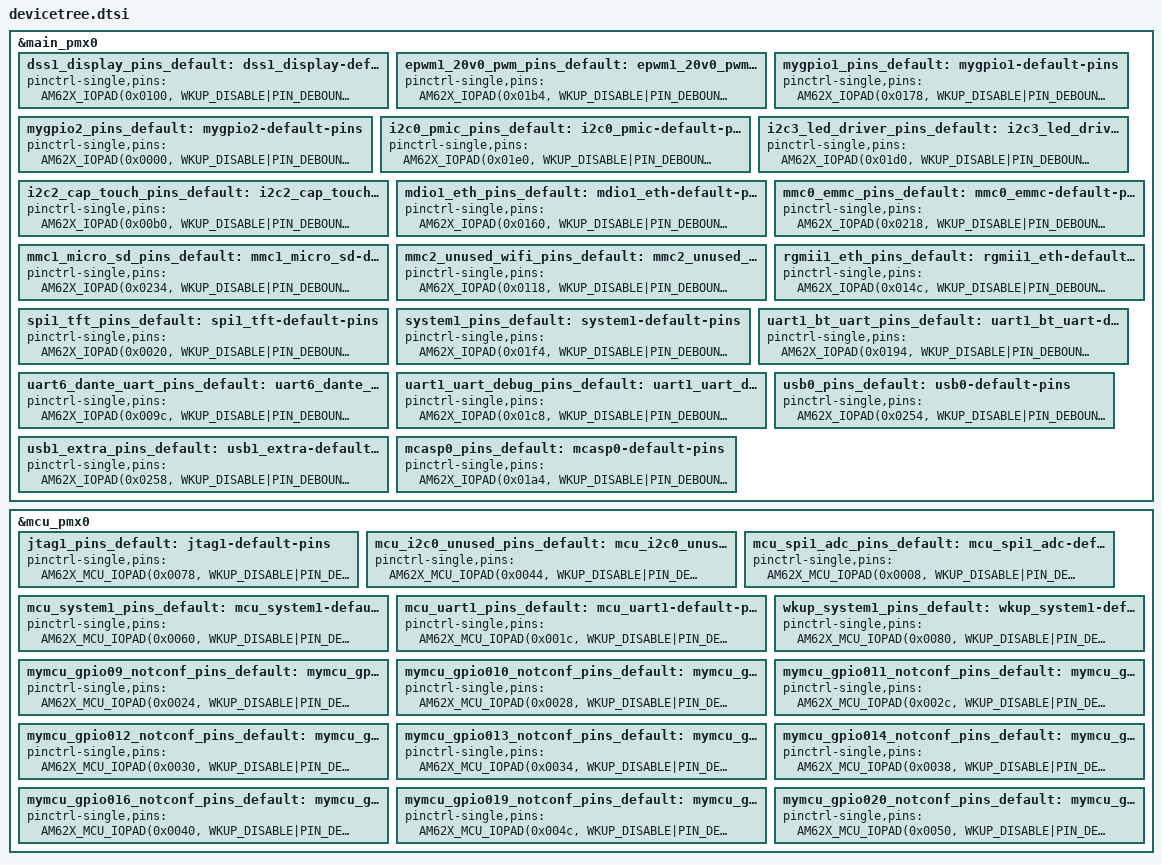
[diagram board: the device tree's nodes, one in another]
/* This file was auto-generated by TI PinMux on 7/21/2026 at 1:33:13 PM. */
/* This file should only be used as a reference. Some pins/peripherals, */
/* depending on your use case, may need additional configuration. */

/* Some or all of the pins from the following groups are not used by the device tree
	ddrss1_ddr_memory
	mcu_osc1
	usb0
	usb1_extra
	wkup_lfosc1
*/

&main_pmx0 {
	dss1_display_pins_default: dss1_display-default-pins {
		pinctrl-single,pins = <
			AM62X_IOPAD(0x0100, WKUP_DISABLE|PIN_DEBOUNCE_DISABLE|PIN_DS_FORCE_DISABLE|PIN_OUTPUT|PIN_DRIVE_STRENGTH_NOMINAL|PIN_DS_ISO_OVERRIDE_DISABLE|PIN_DS_ISO_BYPASS_DISABLE|ACTIVE_STATE_VAL|PIN_DS_INPUT|PIN_SCMITT_TRIGGER_ENABLE, 0) /* (AC25) VOUT0_VSYNC */
			AM62X_IOPAD(0x00f8, WKUP_DISABLE|PIN_DEBOUNCE_DISABLE|PIN_DS_FORCE_DISABLE|PIN_OUTPUT|PIN_DRIVE_STRENGTH_NOMINAL|PIN_DS_ISO_OVERRIDE_DISABLE|PIN_DS_ISO_BYPASS_DISABLE|ACTIVE_STATE_VAL|PIN_DS_INPUT|PIN_SCMITT_TRIGGER_ENABLE, 0) /* (AB24) VOUT0_HSYNC */
			AM62X_IOPAD(0x0104, WKUP_DISABLE|PIN_DEBOUNCE_DISABLE|PIN_DS_FORCE_DISABLE|PIN_OUTPUT|PIN_DRIVE_STRENGTH_NOMINAL|PIN_DS_ISO_OVERRIDE_DISABLE|PIN_DS_ISO_BYPASS_DISABLE|ACTIVE_STATE_VAL|PIN_DS_INPUT|PIN_SCMITT_TRIGGER_ENABLE, 0) /* (AC24) VOUT0_PCLK */
			AM62X_IOPAD(0x00fc, WKUP_DISABLE|PIN_DEBOUNCE_DISABLE|PIN_DS_FORCE_DISABLE|PIN_OUTPUT|PIN_DRIVE_STRENGTH_NOMINAL|PIN_DS_ISO_OVERRIDE_DISABLE|PIN_DS_ISO_BYPASS_DISABLE|ACTIVE_STATE_VAL|PIN_DS_INPUT|PIN_SCMITT_TRIGGER_ENABLE, 0) /* (Y20) VOUT0_DE */
			AM62X_IOPAD(0x00b8, WKUP_DISABLE|PIN_DEBOUNCE_DISABLE|PIN_DS_FORCE_DISABLE|PIN_OUTPUT|PIN_DRIVE_STRENGTH_NOMINAL|PIN_DS_ISO_OVERRIDE_DISABLE|PIN_DS_ISO_BYPASS_DISABLE|ACTIVE_STATE_VAL|PIN_DS_INPUT|PIN_SCMITT_TRIGGER_ENABLE, 0) /* (U22) VOUT0_DATA0 */
			AM62X_IOPAD(0x00bc, WKUP_DISABLE|PIN_DEBOUNCE_DISABLE|PIN_DS_FORCE_DISABLE|PIN_OUTPUT|PIN_DRIVE_STRENGTH_NOMINAL|PIN_DS_ISO_OVERRIDE_DISABLE|PIN_DS_ISO_BYPASS_DISABLE|ACTIVE_STATE_VAL|PIN_DS_INPUT|PIN_SCMITT_TRIGGER_ENABLE, 0) /* (V24) VOUT0_DATA1 */
			AM62X_IOPAD(0x00c0, WKUP_DISABLE|PIN_DEBOUNCE_DISABLE|PIN_DS_FORCE_DISABLE|PIN_OUTPUT|PIN_DRIVE_STRENGTH_NOMINAL|PIN_DS_ISO_OVERRIDE_DISABLE|PIN_DS_ISO_BYPASS_DISABLE|ACTIVE_STATE_VAL|PIN_DS_INPUT|PIN_SCMITT_TRIGGER_ENABLE, 0) /* (W25) VOUT0_DATA2 */
			AM62X_IOPAD(0x00c4, WKUP_DISABLE|PIN_DEBOUNCE_DISABLE|PIN_DS_FORCE_DISABLE|PIN_OUTPUT|PIN_DRIVE_STRENGTH_NOMINAL|PIN_DS_ISO_OVERRIDE_DISABLE|PIN_DS_ISO_BYPASS_DISABLE|ACTIVE_STATE_VAL|PIN_DS_INPUT|PIN_SCMITT_TRIGGER_ENABLE, 0) /* (W24) VOUT0_DATA3 */
			AM62X_IOPAD(0x00c8, WKUP_DISABLE|PIN_DEBOUNCE_DISABLE|PIN_DS_FORCE_DISABLE|PIN_OUTPUT|PIN_DRIVE_STRENGTH_NOMINAL|PIN_DS_ISO_OVERRIDE_DISABLE|PIN_DS_ISO_BYPASS_DISABLE|ACTIVE_STATE_VAL|PIN_DS_INPUT|PIN_SCMITT_TRIGGER_ENABLE, 0) /* (Y25) VOUT0_DATA4 */
			AM62X_IOPAD(0x00cc, WKUP_DISABLE|PIN_DEBOUNCE_DISABLE|PIN_DS_FORCE_DISABLE|PIN_OUTPUT|PIN_DRIVE_STRENGTH_NOMINAL|PIN_DS_ISO_OVERRIDE_DISABLE|PIN_DS_ISO_BYPASS_DISABLE|ACTIVE_STATE_VAL|PIN_DS_INPUT|PIN_SCMITT_TRIGGER_ENABLE, 0) /* (Y24) VOUT0_DATA5 */
			AM62X_IOPAD(0x00d0, WKUP_DISABLE|PIN_DEBOUNCE_DISABLE|PIN_DS_FORCE_DISABLE|PIN_OUTPUT|PIN_DRIVE_STRENGTH_NOMINAL|PIN_DS_ISO_OVERRIDE_DISABLE|PIN_DS_ISO_BYPASS_DISABLE|ACTIVE_STATE_VAL|PIN_DS_INPUT|PIN_SCMITT_TRIGGER_ENABLE, 0) /* (Y23) VOUT0_DATA6 */
			AM62X_IOPAD(0x00d4, WKUP_DISABLE|PIN_DEBOUNCE_DISABLE|PIN_DS_FORCE_DISABLE|PIN_OUTPUT|PIN_DRIVE_STRENGTH_NOMINAL|PIN_DS_ISO_OVERRIDE_DISABLE|PIN_DS_ISO_BYPASS_DISABLE|ACTIVE_STATE_VAL|PIN_DS_INPUT|PIN_SCMITT_TRIGGER_ENABLE, 0) /* (AA25) VOUT0_DATA7 */
			AM62X_IOPAD(0x00d8, WKUP_DISABLE|PIN_DEBOUNCE_DISABLE|PIN_DS_FORCE_DISABLE|PIN_OUTPUT|PIN_DRIVE_STRENGTH_NOMINAL|PIN_DS_ISO_OVERRIDE_DISABLE|PIN_DS_ISO_BYPASS_DISABLE|ACTIVE_STATE_VAL|PIN_DS_INPUT|PIN_SCMITT_TRIGGER_ENABLE, 0) /* (V21) VOUT0_DATA8 */
			AM62X_IOPAD(0x00dc, WKUP_DISABLE|PIN_DEBOUNCE_DISABLE|PIN_DS_FORCE_DISABLE|PIN_OUTPUT|PIN_DRIVE_STRENGTH_NOMINAL|PIN_DS_ISO_OVERRIDE_DISABLE|PIN_DS_ISO_BYPASS_DISABLE|ACTIVE_STATE_VAL|PIN_DS_INPUT|PIN_SCMITT_TRIGGER_ENABLE, 0) /* (W21) VOUT0_DATA9 */
			AM62X_IOPAD(0x00e0, WKUP_DISABLE|PIN_DEBOUNCE_DISABLE|PIN_DS_FORCE_DISABLE|PIN_OUTPUT|PIN_DRIVE_STRENGTH_NOMINAL|PIN_DS_ISO_OVERRIDE_DISABLE|PIN_DS_ISO_BYPASS_DISABLE|ACTIVE_STATE_VAL|PIN_DS_INPUT|PIN_SCMITT_TRIGGER_ENABLE, 0) /* (V20) VOUT0_DATA10 */
			AM62X_IOPAD(0x00e4, WKUP_DISABLE|PIN_DEBOUNCE_DISABLE|PIN_DS_FORCE_DISABLE|PIN_OUTPUT|PIN_DRIVE_STRENGTH_NOMINAL|PIN_DS_ISO_OVERRIDE_DISABLE|PIN_DS_ISO_BYPASS_DISABLE|ACTIVE_STATE_VAL|PIN_DS_INPUT|PIN_SCMITT_TRIGGER_ENABLE, 0) /* (AA23) VOUT0_DATA11 */
			AM62X_IOPAD(0x00e8, WKUP_DISABLE|PIN_DEBOUNCE_DISABLE|PIN_DS_FORCE_DISABLE|PIN_OUTPUT|PIN_DRIVE_STRENGTH_NOMINAL|PIN_DS_ISO_OVERRIDE_DISABLE|PIN_DS_ISO_BYPASS_DISABLE|ACTIVE_STATE_VAL|PIN_DS_INPUT|PIN_SCMITT_TRIGGER_ENABLE, 0) /* (AB25) VOUT0_DATA12 */
			AM62X_IOPAD(0x00ec, WKUP_DISABLE|PIN_DEBOUNCE_DISABLE|PIN_DS_FORCE_DISABLE|PIN_OUTPUT|PIN_DRIVE_STRENGTH_NOMINAL|PIN_DS_ISO_OVERRIDE_DISABLE|PIN_DS_ISO_BYPASS_DISABLE|ACTIVE_STATE_VAL|PIN_DS_INPUT|PIN_SCMITT_TRIGGER_ENABLE, 0) /* (AA24) VOUT0_DATA13 */
			AM62X_IOPAD(0x00f0, WKUP_DISABLE|PIN_DEBOUNCE_DISABLE|PIN_DS_FORCE_DISABLE|PIN_OUTPUT|PIN_DRIVE_STRENGTH_NOMINAL|PIN_DS_ISO_OVERRIDE_DISABLE|PIN_DS_ISO_BYPASS_DISABLE|ACTIVE_STATE_VAL|PIN_DS_INPUT|PIN_SCMITT_TRIGGER_ENABLE, 0) /* (Y22) VOUT0_DATA14 */
			AM62X_IOPAD(0x00f4, WKUP_DISABLE|PIN_DEBOUNCE_DISABLE|PIN_DS_FORCE_DISABLE|PIN_OUTPUT|PIN_DRIVE_STRENGTH_NOMINAL|PIN_DS_ISO_OVERRIDE_DISABLE|PIN_DS_ISO_BYPASS_DISABLE|ACTIVE_STATE_VAL|PIN_DS_INPUT|PIN_SCMITT_TRIGGER_ENABLE, 0) /* (AA21) VOUT0_DATA15 */
			AM62X_IOPAD(0x005c, WKUP_DISABLE|PIN_DEBOUNCE_DISABLE|PIN_DS_FORCE_DISABLE|PIN_OUTPUT|PIN_DRIVE_STRENGTH_NOMINAL|PIN_DS_ISO_OVERRIDE_DISABLE|PIN_DS_ISO_BYPASS_DISABLE|ACTIVE_STATE_VAL|PIN_DS_INPUT|PIN_SCMITT_TRIGGER_ENABLE, 1) /* (R24) GPMC0_AD8.VOUT0_DATA16 */
			AM62X_IOPAD(0x0060, WKUP_DISABLE|PIN_DEBOUNCE_DISABLE|PIN_DS_FORCE_DISABLE|PIN_OUTPUT|PIN_DRIVE_STRENGTH_NOMINAL|PIN_DS_ISO_OVERRIDE_DISABLE|PIN_DS_ISO_BYPASS_DISABLE|ACTIVE_STATE_VAL|PIN_DS_INPUT|PIN_SCMITT_TRIGGER_ENABLE, 1) /* (R25) GPMC0_AD9.VOUT0_DATA17 */
			AM62X_IOPAD(0x0064, WKUP_DISABLE|PIN_DEBOUNCE_DISABLE|PIN_DS_FORCE_DISABLE|PIN_OUTPUT|PIN_DRIVE_STRENGTH_NOMINAL|PIN_DS_ISO_OVERRIDE_DISABLE|PIN_DS_ISO_BYPASS_DISABLE|ACTIVE_STATE_VAL|PIN_DS_INPUT|PIN_SCMITT_TRIGGER_ENABLE, 1) /* (T25) GPMC0_AD10.VOUT0_DATA18 */
			AM62X_IOPAD(0x0068, WKUP_DISABLE|PIN_DEBOUNCE_DISABLE|PIN_DS_FORCE_DISABLE|PIN_OUTPUT|PIN_DRIVE_STRENGTH_NOMINAL|PIN_DS_ISO_OVERRIDE_DISABLE|PIN_DS_ISO_BYPASS_DISABLE|ACTIVE_STATE_VAL|PIN_DS_INPUT|PIN_SCMITT_TRIGGER_ENABLE, 1) /* (R21) GPMC0_AD11.VOUT0_DATA19 */
			AM62X_IOPAD(0x006c, WKUP_DISABLE|PIN_DEBOUNCE_DISABLE|PIN_DS_FORCE_DISABLE|PIN_OUTPUT|PIN_DRIVE_STRENGTH_NOMINAL|PIN_DS_ISO_OVERRIDE_DISABLE|PIN_DS_ISO_BYPASS_DISABLE|ACTIVE_STATE_VAL|PIN_DS_INPUT|PIN_SCMITT_TRIGGER_ENABLE, 1) /* (T22) GPMC0_AD12.VOUT0_DATA20 */
			AM62X_IOPAD(0x0070, WKUP_DISABLE|PIN_DEBOUNCE_DISABLE|PIN_DS_FORCE_DISABLE|PIN_OUTPUT|PIN_DRIVE_STRENGTH_NOMINAL|PIN_DS_ISO_OVERRIDE_DISABLE|PIN_DS_ISO_BYPASS_DISABLE|ACTIVE_STATE_VAL|PIN_DS_INPUT|PIN_SCMITT_TRIGGER_ENABLE, 1) /* (T24) GPMC0_AD13.VOUT0_DATA21 */
			AM62X_IOPAD(0x0074, WKUP_DISABLE|PIN_DEBOUNCE_DISABLE|PIN_DS_FORCE_DISABLE|PIN_OUTPUT|PIN_DRIVE_STRENGTH_NOMINAL|PIN_DS_ISO_OVERRIDE_DISABLE|PIN_DS_ISO_BYPASS_DISABLE|ACTIVE_STATE_VAL|PIN_DS_INPUT|PIN_SCMITT_TRIGGER_ENABLE, 1) /* (U25) GPMC0_AD14.VOUT0_DATA22 */
			AM62X_IOPAD(0x0078, WKUP_DISABLE|PIN_DEBOUNCE_DISABLE|PIN_DS_FORCE_DISABLE|PIN_OUTPUT|PIN_DRIVE_STRENGTH_NOMINAL|PIN_DS_ISO_OVERRIDE_DISABLE|PIN_DS_ISO_BYPASS_DISABLE|ACTIVE_STATE_VAL|PIN_DS_INPUT|PIN_SCMITT_TRIGGER_ENABLE, 1) /* (U24) GPMC0_AD15.VOUT0_DATA23 */
		>;
	};
	epwm1_20v0_pwm_pins_default: epwm1_20v0_pwm-default-pins {
		pinctrl-single,pins = <
			AM62X_IOPAD(0x01b4, WKUP_DISABLE|PIN_DEBOUNCE_DISABLE|PIN_DS_FORCE_DISABLE|PIN_OUTPUT|PIN_DRIVE_STRENGTH_NOMINAL|PIN_DS_ISO_OVERRIDE_DISABLE|PIN_DS_ISO_BYPASS_DISABLE|ACTIVE_STATE_VAL|PIN_DS_INPUT|PIN_SCMITT_TRIGGER_ENABLE, 2) /* (A13) SPI0_CS0.EHRPWM0_A */
		>;
	};
	mygpio1_pins_default: mygpio1-default-pins {
		pinctrl-single,pins = <
			AM62X_IOPAD(0x0178, WKUP_DISABLE|PIN_DEBOUNCE_DISABLE|PIN_DS_FORCE_DISABLE|PIN_INPUT|PIN_DRIVE_STRENGTH_NOMINAL|PIN_DS_ISO_OVERRIDE_DISABLE|PIN_DS_ISO_BYPASS_DISABLE|ACTIVE_STATE_VAL|PIN_DS_INPUT|PIN_SCMITT_TRIGGER_ENABLE, 7) /* (AC20) RGMII2_TD3.GPIO1_0 GPIO1_0_USB0_Ocn */
			AM62X_IOPAD(0x0028, WKUP_DISABLE|PIN_DEBOUNCE_DISABLE|PIN_DS_FORCE_DISABLE|PIN_INPUT|PIN_DRIVE_STRENGTH_NOMINAL|PIN_DS_ISO_OVERRIDE_DISABLE|PIN_DS_ISO_BYPASS_DISABLE|ACTIVE_STATE_VAL|PIN_DS_INPUT|PIN_SCMITT_TRIGGER_ENABLE, 7) /* (J22) OSPI0_D7.GPIO0_10 GPIO0_10_LED1 */
			AM62X_IOPAD(0x003c, WKUP_DISABLE|PIN_DEBOUNCE_DISABLE|PIN_DS_FORCE_DISABLE|PIN_INPUT|PIN_DRIVE_STRENGTH_NOMINAL|PIN_DS_ISO_OVERRIDE_DISABLE|PIN_DS_ISO_BYPASS_DISABLE|ACTIVE_STATE_VAL|PIN_DS_INPUT|PIN_SCMITT_TRIGGER_ENABLE, 7) /* (M25) GPMC0_AD0.GPIO0_15 BOOTMODE00 */
			AM62X_IOPAD(0x0040, WKUP_DISABLE|PIN_DEBOUNCE_DISABLE|PIN_DS_FORCE_DISABLE|PIN_INPUT|PIN_DRIVE_STRENGTH_NOMINAL|PIN_DS_ISO_OVERRIDE_DISABLE|PIN_DS_ISO_BYPASS_DISABLE|ACTIVE_STATE_VAL|PIN_DS_INPUT|PIN_SCMITT_TRIGGER_ENABLE, 7) /* (N23) GPMC0_AD1.GPIO0_16 BOOTMODE01_eMMC_nRST */
			AM62X_IOPAD(0x0044, WKUP_DISABLE|PIN_DEBOUNCE_DISABLE|PIN_DS_FORCE_DISABLE|PIN_INPUT|PIN_DRIVE_STRENGTH_NOMINAL|PIN_DS_ISO_OVERRIDE_DISABLE|PIN_DS_ISO_BYPASS_DISABLE|ACTIVE_STATE_VAL|PIN_DS_INPUT|PIN_SCMITT_TRIGGER_ENABLE, 7) /* (N24) GPMC0_AD2.GPIO0_17 BOOTMODE02 */
			AM62X_IOPAD(0x018c, WKUP_DISABLE|PIN_DEBOUNCE_DISABLE|PIN_DS_FORCE_DISABLE|PIN_INPUT|PIN_DRIVE_STRENGTH_NOMINAL|PIN_DS_ISO_OVERRIDE_DISABLE|PIN_DS_ISO_BYPASS_DISABLE|ACTIVE_STATE_VAL|PIN_DS_INPUT|PIN_SCMITT_TRIGGER_ENABLE, 7) /* (AC21) RGMII2_RD2.GPIO1_5 GPIO1_3_KNOB_I2C_nRST */
			AM62X_IOPAD(0x0190, WKUP_DISABLE|PIN_DEBOUNCE_DISABLE|PIN_DS_FORCE_DISABLE|PIN_INPUT|PIN_DRIVE_STRENGTH_NOMINAL|PIN_DS_ISO_OVERRIDE_DISABLE|PIN_DS_ISO_BYPASS_DISABLE|ACTIVE_STATE_VAL|PIN_DS_INPUT|PIN_SCMITT_TRIGGER_ENABLE, 7) /* (AE22) RGMII2_RD3.GPIO1_6 GPIO1_6_AVAILABLE */
			AM62X_IOPAD(0x0048, WKUP_DISABLE|PIN_DEBOUNCE_DISABLE|PIN_DS_FORCE_DISABLE|PIN_INPUT|PIN_DRIVE_STRENGTH_NOMINAL|PIN_DS_ISO_OVERRIDE_DISABLE|PIN_DS_ISO_BYPASS_DISABLE|ACTIVE_STATE_VAL|PIN_DS_INPUT|PIN_SCMITT_TRIGGER_ENABLE, 7) /* (N25) GPMC0_AD3.GPIO0_18 BOOTMODE03 */
			AM62X_IOPAD(0x01bc, WKUP_DISABLE|PIN_DEBOUNCE_DISABLE|PIN_DS_FORCE_DISABLE|PIN_INPUT|PIN_DRIVE_STRENGTH_NOMINAL|PIN_DS_ISO_OVERRIDE_DISABLE|PIN_DS_ISO_BYPASS_DISABLE|ACTIVE_STATE_VAL|PIN_DS_INPUT|PIN_SCMITT_TRIGGER_ENABLE, 7) /* (A14) SPI0_CLK.GPIO1_17 GPIO1_17_AVAILABLE */
			AM62X_IOPAD(0x004c, WKUP_DISABLE|PIN_DEBOUNCE_DISABLE|PIN_DS_FORCE_DISABLE|PIN_INPUT|PIN_DRIVE_STRENGTH_NOMINAL|PIN_DS_ISO_OVERRIDE_DISABLE|PIN_DS_ISO_BYPASS_DISABLE|ACTIVE_STATE_VAL|PIN_DS_INPUT|PIN_SCMITT_TRIGGER_ENABLE, 7) /* (P24) GPMC0_AD4.GPIO0_19 BOOTMODE04 */
			AM62X_IOPAD(0x0050, WKUP_DISABLE|PIN_DEBOUNCE_DISABLE|PIN_DS_FORCE_DISABLE|PIN_INPUT|PIN_DRIVE_STRENGTH_NOMINAL|PIN_DS_ISO_OVERRIDE_DISABLE|PIN_DS_ISO_BYPASS_DISABLE|ACTIVE_STATE_VAL|PIN_DS_INPUT|PIN_SCMITT_TRIGGER_ENABLE, 7) /* (P22) GPMC0_AD5.GPIO0_20 BOOTMODE05 */
		>;
	};
	mygpio2_pins_default: mygpio2-default-pins {
		pinctrl-single,pins = <
			AM62X_IOPAD(0x0000, WKUP_DISABLE|PIN_DEBOUNCE_DISABLE|PIN_DS_FORCE_DISABLE|PIN_INPUT|PIN_DRIVE_STRENGTH_NOMINAL|PIN_DS_ISO_OVERRIDE_DISABLE|PIN_DS_ISO_BYPASS_DISABLE|ACTIVE_STATE_VAL|PIN_DS_INPUT|PIN_SCMITT_TRIGGER_ENABLE, 7) /* (H24) OSPI0_CLK.GPIO0_0 GPIO0_0_ULT_MUTE */
			AM62X_IOPAD(0x0004, WKUP_DISABLE|PIN_DEBOUNCE_DISABLE|PIN_DS_FORCE_DISABLE|PIN_INPUT|PIN_DRIVE_STRENGTH_NOMINAL|PIN_DS_ISO_OVERRIDE_DISABLE|PIN_DS_ISO_BYPASS_DISABLE|ACTIVE_STATE_VAL|PIN_DS_INPUT|PIN_SCMITT_TRIGGER_ENABLE, 7) /* (G25) OSPI0_LBCLKO.GPIO0_1 GPIO0_1_CTP_RST */
			AM62X_IOPAD(0x0008, WKUP_DISABLE|PIN_DEBOUNCE_DISABLE|PIN_DS_FORCE_DISABLE|PIN_INPUT|PIN_DRIVE_STRENGTH_NOMINAL|PIN_DS_ISO_OVERRIDE_DISABLE|PIN_DS_ISO_BYPASS_DISABLE|ACTIVE_STATE_VAL|PIN_DS_INPUT|PIN_SCMITT_TRIGGER_ENABLE, 7) /* (J24) OSPI0_DQS.GPIO0_2 GPIO0_2_RTC_nINT */
			AM62X_IOPAD(0x000c, WKUP_DISABLE|PIN_DEBOUNCE_DISABLE|PIN_DS_FORCE_DISABLE|PIN_INPUT|PIN_DRIVE_STRENGTH_NOMINAL|PIN_DS_ISO_OVERRIDE_DISABLE|PIN_DS_ISO_BYPASS_DISABLE|ACTIVE_STATE_VAL|PIN_DS_INPUT|PIN_SCMITT_TRIGGER_ENABLE, 7) /* (E25) OSPI0_D0.GPIO0_3 GPIO0_3_LED_CTRL_nRESET */
			AM62X_IOPAD(0x0010, WKUP_DISABLE|PIN_DEBOUNCE_DISABLE|PIN_DS_FORCE_DISABLE|PIN_INPUT|PIN_DRIVE_STRENGTH_NOMINAL|PIN_DS_ISO_OVERRIDE_DISABLE|PIN_DS_ISO_BYPASS_DISABLE|ACTIVE_STATE_VAL|PIN_DS_INPUT|PIN_SCMITT_TRIGGER_ENABLE, 7) /* (G24) OSPI0_D1.GPIO0_4 GPIO0_4_TFT_SLEEP */
			AM62X_IOPAD(0x0014, WKUP_DISABLE|PIN_DEBOUNCE_DISABLE|PIN_DS_FORCE_DISABLE|PIN_INPUT|PIN_DRIVE_STRENGTH_NOMINAL|PIN_DS_ISO_OVERRIDE_DISABLE|PIN_DS_ISO_BYPASS_DISABLE|ACTIVE_STATE_VAL|PIN_DS_INPUT|PIN_SCMITT_TRIGGER_ENABLE, 7) /* (F25) OSPI0_D2.GPIO0_5 GPIO0_5_3V3_G_EN */
			AM62X_IOPAD(0x0018, WKUP_DISABLE|PIN_DEBOUNCE_DISABLE|PIN_DS_FORCE_DISABLE|PIN_INPUT|PIN_DRIVE_STRENGTH_NOMINAL|PIN_DS_ISO_OVERRIDE_DISABLE|PIN_DS_ISO_BYPASS_DISABLE|ACTIVE_STATE_VAL|PIN_DS_INPUT|PIN_SCMITT_TRIGGER_ENABLE, 7) /* (F24) OSPI0_D3.GPIO0_6 GPIO0_6_DANTE_nRST */
			AM62X_IOPAD(0x0054, WKUP_DISABLE|PIN_DEBOUNCE_DISABLE|PIN_DS_FORCE_DISABLE|PIN_INPUT|PIN_DRIVE_STRENGTH_NOMINAL|PIN_DS_ISO_OVERRIDE_DISABLE|PIN_DS_ISO_BYPASS_DISABLE|ACTIVE_STATE_VAL|PIN_DS_INPUT|PIN_SCMITT_TRIGGER_ENABLE, 7) /* (P21) GPMC0_AD6.GPIO0_21 BOOTMODE06 */
			AM62X_IOPAD(0x002c, WKUP_DISABLE|PIN_DEBOUNCE_DISABLE|PIN_DS_FORCE_DISABLE|PIN_INPUT|PIN_DRIVE_STRENGTH_NOMINAL|PIN_DS_ISO_OVERRIDE_DISABLE|PIN_DS_ISO_BYPASS_DISABLE|ACTIVE_STATE_VAL|PIN_DS_INPUT|PIN_SCMITT_TRIGGER_ENABLE, 7) /* (F23) OSPI0_CSn0.GPIO0_11 GPIO0_11_AVAILABLE */
			AM62X_IOPAD(0x0030, WKUP_DISABLE|PIN_DEBOUNCE_DISABLE|PIN_DS_FORCE_DISABLE|PIN_INPUT|PIN_DRIVE_STRENGTH_NOMINAL|PIN_DS_ISO_OVERRIDE_DISABLE|PIN_DS_ISO_BYPASS_DISABLE|ACTIVE_STATE_VAL|PIN_DS_INPUT|PIN_SCMITT_TRIGGER_ENABLE, 7) /* (G21) OSPI0_CSn1.GPIO0_12 GPIO0_12_PHY_nRST */
			AM62X_IOPAD(0x0034, WKUP_DISABLE|PIN_DEBOUNCE_DISABLE|PIN_DS_FORCE_DISABLE|PIN_INPUT|PIN_DRIVE_STRENGTH_NOMINAL|PIN_DS_ISO_OVERRIDE_DISABLE|PIN_DS_ISO_BYPASS_DISABLE|ACTIVE_STATE_VAL|PIN_DS_INPUT|PIN_SCMITT_TRIGGER_ENABLE, 7) /* (H21) OSPI0_CSn2.GPIO0_13 GPIO0_13_LCD_RESET */
			AM62X_IOPAD(0x0038, WKUP_DISABLE|PIN_DEBOUNCE_DISABLE|PIN_DS_FORCE_DISABLE|PIN_INPUT|PIN_DRIVE_STRENGTH_NOMINAL|PIN_DS_ISO_OVERRIDE_DISABLE|PIN_DS_ISO_BYPASS_DISABLE|ACTIVE_STATE_VAL|PIN_DS_INPUT|PIN_SCMITT_TRIGGER_ENABLE, 7) /* (E24) OSPI0_CSn3.GPIO0_14 GPIO0_14_BT_GPIO1 */
			AM62X_IOPAD(0x0058, WKUP_DISABLE|PIN_DEBOUNCE_DISABLE|PIN_DS_FORCE_DISABLE|PIN_INPUT|PIN_DRIVE_STRENGTH_NOMINAL|PIN_DS_ISO_OVERRIDE_DISABLE|PIN_DS_ISO_BYPASS_DISABLE|ACTIVE_STATE_VAL|PIN_DS_INPUT|PIN_SCMITT_TRIGGER_ENABLE, 7) /* (R23) GPMC0_AD7.GPIO0_22 BOOTMODE07 */
			AM62X_IOPAD(0x007c, WKUP_DISABLE|PIN_DEBOUNCE_DISABLE|PIN_DS_FORCE_DISABLE|PIN_INPUT|PIN_DRIVE_STRENGTH_NOMINAL|PIN_DS_ISO_OVERRIDE_DISABLE|PIN_DS_ISO_BYPASS_DISABLE|ACTIVE_STATE_VAL|PIN_DS_INPUT|PIN_SCMITT_TRIGGER_ENABLE, 7) /* (P25) GPMC0_CLK.GPIO0_31 GPIO0_31_BT_nRST */
			AM62X_IOPAD(0x0084, WKUP_DISABLE|PIN_DEBOUNCE_DISABLE|PIN_DS_FORCE_DISABLE|PIN_INPUT|PIN_DRIVE_STRENGTH_NOMINAL|PIN_DS_ISO_OVERRIDE_DISABLE|PIN_DS_ISO_BYPASS_DISABLE|ACTIVE_STATE_VAL|PIN_DS_INPUT|PIN_SCMITT_TRIGGER_ENABLE, 7) /* (L23) GPMC0_ADVn_ALE.GPIO0_32 GPIO0_32_VAR_2 */
			AM62X_IOPAD(0x016c, WKUP_DISABLE|PIN_DEBOUNCE_DISABLE|PIN_DS_FORCE_DISABLE|PIN_INPUT|PIN_DRIVE_STRENGTH_NOMINAL|PIN_DS_ISO_OVERRIDE_DISABLE|PIN_DS_ISO_BYPASS_DISABLE|ACTIVE_STATE_VAL|PIN_DS_INPUT|PIN_SCMITT_TRIGGER_ENABLE, 7) /* (Y18) RGMII2_TD0.GPIO0_89 GPIO0_89_WL_nRST */
			AM62X_IOPAD(0x0088, WKUP_DISABLE|PIN_DEBOUNCE_DISABLE|PIN_DS_FORCE_DISABLE|PIN_INPUT|PIN_DRIVE_STRENGTH_NOMINAL|PIN_DS_ISO_OVERRIDE_DISABLE|PIN_DS_ISO_BYPASS_DISABLE|ACTIVE_STATE_VAL|PIN_DS_INPUT|PIN_SCMITT_TRIGGER_ENABLE, 7) /* (L24) GPMC0_OEn_REn.GPIO0_33 GPIO0_33_AVAILABLE */
			AM62X_IOPAD(0x008c, WKUP_DISABLE|PIN_DEBOUNCE_DISABLE|PIN_DS_FORCE_DISABLE|PIN_INPUT|PIN_DRIVE_STRENGTH_NOMINAL|PIN_DS_ISO_OVERRIDE_DISABLE|PIN_DS_ISO_BYPASS_DISABLE|ACTIVE_STATE_VAL|PIN_DS_INPUT|PIN_SCMITT_TRIGGER_ENABLE, 7) /* (L25) GPMC0_WEn.GPIO0_34 GPIO0_34_AVAILABLE */
			AM62X_IOPAD(0x0090, WKUP_DISABLE|PIN_DEBOUNCE_DISABLE|PIN_DS_FORCE_DISABLE|PIN_INPUT|PIN_DRIVE_STRENGTH_NOMINAL|PIN_DS_ISO_OVERRIDE_DISABLE|PIN_DS_ISO_BYPASS_DISABLE|ACTIVE_STATE_VAL|PIN_DS_INPUT|PIN_SCMITT_TRIGGER_ENABLE, 7) /* (M24) GPMC0_BE0n_CLE.GPIO0_35 GPIO0_35_VAR_1 */
			AM62X_IOPAD(0x0094, WKUP_DISABLE|PIN_DEBOUNCE_DISABLE|PIN_DS_FORCE_DISABLE|PIN_INPUT|PIN_DRIVE_STRENGTH_NOMINAL|PIN_DS_ISO_OVERRIDE_DISABLE|PIN_DS_ISO_BYPASS_DISABLE|ACTIVE_STATE_VAL|PIN_DS_INPUT|PIN_SCMITT_TRIGGER_ENABLE, 7) /* (N20) GPMC0_BE1n.GPIO0_36 GPIO0_36_VAR_0 */
			AM62X_IOPAD(0x0098, WKUP_DISABLE|PIN_DEBOUNCE_DISABLE|PIN_DS_FORCE_DISABLE|PIN_INPUT|PIN_DRIVE_STRENGTH_NOMINAL|PIN_DS_ISO_OVERRIDE_DISABLE|PIN_DS_ISO_BYPASS_DISABLE|ACTIVE_STATE_VAL|PIN_DS_INPUT|PIN_SCMITT_TRIGGER_ENABLE, 7) /* (U23) GPMC0_WAIT0.GPIO0_37 GPIO0_37_AVAILABLE */
			AM62X_IOPAD(0x00a4, WKUP_DISABLE|PIN_DEBOUNCE_DISABLE|PIN_DS_FORCE_DISABLE|PIN_INPUT|PIN_DRIVE_STRENGTH_NOMINAL|PIN_DS_ISO_OVERRIDE_DISABLE|PIN_DS_ISO_BYPASS_DISABLE|ACTIVE_STATE_VAL|PIN_DS_INPUT|PIN_SCMITT_TRIGGER_ENABLE, 7) /* (M22) GPMC0_DIR.GPIO0_40 GPIO0_40_BT_PDn */
			AM62X_IOPAD(0x00a8, WKUP_DISABLE|PIN_DEBOUNCE_DISABLE|PIN_DS_FORCE_DISABLE|PIN_INPUT|PIN_DRIVE_STRENGTH_NOMINAL|PIN_DS_ISO_OVERRIDE_DISABLE|PIN_DS_ISO_BYPASS_DISABLE|ACTIVE_STATE_VAL|PIN_DS_INPUT|PIN_SCMITT_TRIGGER_ENABLE, 7) /* (M21) GPMC0_CSn0.GPIO0_41 GPIO0_41_AVAILABLE */
			AM62X_IOPAD(0x00ac, WKUP_DISABLE|PIN_DEBOUNCE_DISABLE|PIN_DS_FORCE_DISABLE|PIN_INPUT|PIN_DRIVE_STRENGTH_NOMINAL|PIN_DS_ISO_OVERRIDE_DISABLE|PIN_DS_ISO_BYPASS_DISABLE|ACTIVE_STATE_VAL|PIN_DS_INPUT|PIN_SCMITT_TRIGGER_ENABLE, 7) /* (L21) GPMC0_CSn1.GPIO0_42 GPIO0_42_AVAILABLE */
			AM62X_IOPAD(0x0164, WKUP_DISABLE|PIN_DEBOUNCE_DISABLE|PIN_DS_FORCE_DISABLE|PIN_INPUT|PIN_DRIVE_STRENGTH_NOMINAL|PIN_DS_ISO_OVERRIDE_DISABLE|PIN_DS_ISO_BYPASS_DISABLE|ACTIVE_STATE_VAL|PIN_DS_INPUT|PIN_SCMITT_TRIGGER_ENABLE, 7) /* (AA19) RGMII2_TX_CTL.GPIO0_87 GPIO0_87_AVAILABLE */
			AM62X_IOPAD(0x0168, WKUP_DISABLE|PIN_DEBOUNCE_DISABLE|PIN_DS_FORCE_DISABLE|PIN_INPUT|PIN_DRIVE_STRENGTH_NOMINAL|PIN_DS_ISO_OVERRIDE_DISABLE|PIN_DS_ISO_BYPASS_DISABLE|ACTIVE_STATE_VAL|PIN_DS_INPUT|PIN_SCMITT_TRIGGER_ENABLE, 7) /* (AE21) RGMII2_TXC.GPIO0_88 GPIO0_88_AVAILABLE */
			AM62X_IOPAD(0x0170, WKUP_DISABLE|PIN_DEBOUNCE_DISABLE|PIN_DS_FORCE_DISABLE|PIN_INPUT|PIN_DRIVE_STRENGTH_NOMINAL|PIN_DS_ISO_OVERRIDE_DISABLE|PIN_DS_ISO_BYPASS_DISABLE|ACTIVE_STATE_VAL|PIN_DS_INPUT|PIN_SCMITT_TRIGGER_ENABLE, 7) /* (AA18) RGMII2_TD1.GPIO0_90 GPIO0_90_BT_nWAKE */
			AM62X_IOPAD(0x0174, WKUP_DISABLE|PIN_DEBOUNCE_DISABLE|PIN_DS_FORCE_DISABLE|PIN_INPUT|PIN_DRIVE_STRENGTH_NOMINAL|PIN_DS_ISO_OVERRIDE_DISABLE|PIN_DS_ISO_BYPASS_DISABLE|ACTIVE_STATE_VAL|PIN_DS_INPUT|PIN_SCMITT_TRIGGER_ENABLE, 7) /* (AD21) RGMII2_TD2.GPIO0_91 GPIO0_91_AVAILABLE */
			AM62X_IOPAD(0x017c, WKUP_DISABLE|PIN_DEBOUNCE_DISABLE|PIN_DS_FORCE_DISABLE|PIN_INPUT|PIN_DRIVE_STRENGTH_NOMINAL|PIN_DS_ISO_OVERRIDE_DISABLE|PIN_DS_ISO_BYPASS_DISABLE|ACTIVE_STATE_VAL|PIN_DS_INPUT|PIN_SCMITT_TRIGGER_ENABLE, 7) /* (AD22) RGMII2_RX_CTL.GPIO1_1 GPIO1_1_CTP_INT */
			AM62X_IOPAD(0x0180, WKUP_DISABLE|PIN_DEBOUNCE_DISABLE|PIN_DS_FORCE_DISABLE|PIN_INPUT|PIN_DRIVE_STRENGTH_NOMINAL|PIN_DS_ISO_OVERRIDE_DISABLE|PIN_DS_ISO_BYPASS_DISABLE|ACTIVE_STATE_VAL|PIN_DS_INPUT|PIN_SCMITT_TRIGGER_ENABLE, 7) /* (AD23) RGMII2_RXC.GPIO1_2 GPIO1_2_KNOB_I2C_INT */
			AM62X_IOPAD(0x0184, WKUP_DISABLE|PIN_DEBOUNCE_DISABLE|PIN_DS_FORCE_DISABLE|PIN_INPUT|PIN_DRIVE_STRENGTH_NOMINAL|PIN_DS_ISO_OVERRIDE_DISABLE|PIN_DS_ISO_BYPASS_DISABLE|ACTIVE_STATE_VAL|PIN_DS_INPUT|PIN_SCMITT_TRIGGER_ENABLE, 7) /* (AE23) RGMII2_RD0.GPIO1_3 GPIO1_3_FACTORY_RESET */
			AM62X_IOPAD(0x0188, WKUP_DISABLE|PIN_DEBOUNCE_DISABLE|PIN_DS_FORCE_DISABLE|PIN_INPUT|PIN_DRIVE_STRENGTH_NOMINAL|PIN_DS_ISO_OVERRIDE_DISABLE|PIN_DS_ISO_BYPASS_DISABLE|ACTIVE_STATE_VAL|PIN_DS_INPUT|PIN_SCMITT_TRIGGER_ENABLE, 7) /* (AB20) RGMII2_RD1.GPIO1_4 GPIO1_4_BT_INT */
			AM62X_IOPAD(0x01b8, WKUP_DISABLE|PIN_DEBOUNCE_DISABLE|PIN_DS_FORCE_DISABLE|PIN_INPUT|PIN_DRIVE_STRENGTH_NOMINAL|PIN_DS_ISO_OVERRIDE_DISABLE|PIN_DS_ISO_BYPASS_DISABLE|ACTIVE_STATE_VAL|PIN_DS_INPUT|PIN_SCMITT_TRIGGER_ENABLE, 7) /* (C13) SPI0_CS1.GPIO1_16 GPIO1_16_LED3 */
			AM62X_IOPAD(0x01c0, WKUP_DISABLE|PIN_DEBOUNCE_DISABLE|PIN_DS_FORCE_DISABLE|PIN_INPUT|PIN_DRIVE_STRENGTH_NOMINAL|PIN_DS_ISO_OVERRIDE_DISABLE|PIN_DS_ISO_BYPASS_DISABLE|ACTIVE_STATE_VAL|PIN_DS_INPUT|PIN_SCMITT_TRIGGER_ENABLE, 7) /* (B13) SPI0_D0.GPIO1_18 GPIO1_18_LED2 */
			AM62X_IOPAD(0x01c4, WKUP_DISABLE|PIN_DEBOUNCE_DISABLE|PIN_DS_FORCE_DISABLE|PIN_INPUT|PIN_DRIVE_STRENGTH_NOMINAL|PIN_DS_ISO_OVERRIDE_DISABLE|PIN_DS_ISO_BYPASS_DISABLE|ACTIVE_STATE_VAL|PIN_DS_INPUT|PIN_SCMITT_TRIGGER_ENABLE, 7) /* (B14) SPI0_D1.GPIO1_19 GPIO1_19_LED0 */
			AM62X_IOPAD(0x01d8, WKUP_DISABLE|PIN_DEBOUNCE_DISABLE|PIN_DS_FORCE_DISABLE|PIN_INPUT|PIN_DRIVE_STRENGTH_NOMINAL|PIN_DS_ISO_OVERRIDE_DISABLE|PIN_DS_ISO_BYPASS_DISABLE|ACTIVE_STATE_VAL|PIN_DS_INPUT|PIN_SCMITT_TRIGGER_ENABLE, 7) /* (C15) MCAN0_TX.GPIO1_24 MCAN0_TX_AVAILABLE */
			AM62X_IOPAD(0x01dc, WKUP_DISABLE|PIN_DEBOUNCE_DISABLE|PIN_DS_FORCE_DISABLE|PIN_INPUT|PIN_DRIVE_STRENGTH_NOMINAL|PIN_DS_ISO_OVERRIDE_DISABLE|PIN_DS_ISO_BYPASS_DISABLE|ACTIVE_STATE_VAL|PIN_DS_INPUT|PIN_SCMITT_TRIGGER_ENABLE, 7) /* (E15) MCAN0_RX.GPIO1_25 MCAN0_RX_AVAILABLE */
		>;
	};
	i2c0_pmic_pins_default: i2c0_pmic-default-pins {
		pinctrl-single,pins = <
			AM62X_IOPAD(0x01e0, WKUP_DISABLE|PIN_DEBOUNCE_DISABLE|PIN_DS_FORCE_DISABLE|PIN_INPUT|PIN_DRIVE_STRENGTH_NOMINAL|PIN_DS_ISO_OVERRIDE_DISABLE|PIN_DS_ISO_BYPASS_DISABLE|ACTIVE_STATE_VAL|PIN_DS_INPUT|PIN_SCMITT_TRIGGER_ENABLE, 0) /* (B16) I2C0_SCL */
			AM62X_IOPAD(0x01e4, WKUP_DISABLE|PIN_DEBOUNCE_DISABLE|PIN_DS_FORCE_DISABLE|PIN_INPUT|PIN_DRIVE_STRENGTH_NOMINAL|PIN_DS_ISO_OVERRIDE_DISABLE|PIN_DS_ISO_BYPASS_DISABLE|ACTIVE_STATE_VAL|PIN_DS_INPUT|PIN_SCMITT_TRIGGER_ENABLE, 0) /* (A16) I2C0_SDA */
		>;
	};
	i2c3_led_driver_pins_default: i2c3_led_driver-default-pins {
		pinctrl-single,pins = <
			AM62X_IOPAD(0x01d0, WKUP_DISABLE|PIN_DEBOUNCE_DISABLE|PIN_DS_FORCE_DISABLE|PIN_INPUT|PIN_DRIVE_STRENGTH_NOMINAL|PIN_DS_ISO_OVERRIDE_DISABLE|PIN_DS_ISO_BYPASS_DISABLE|ACTIVE_STATE_VAL|PIN_DS_INPUT|PIN_SCMITT_TRIGGER_ENABLE, 2) /* (A15) UART0_CTSn.I2C3_SCL */
			AM62X_IOPAD(0x01d4, WKUP_DISABLE|PIN_DEBOUNCE_DISABLE|PIN_DS_FORCE_DISABLE|PIN_INPUT|PIN_DRIVE_STRENGTH_NOMINAL|PIN_DS_ISO_OVERRIDE_DISABLE|PIN_DS_ISO_BYPASS_DISABLE|ACTIVE_STATE_VAL|PIN_DS_INPUT|PIN_SCMITT_TRIGGER_ENABLE, 2) /* (B15) UART0_RTSn.I2C3_SDA */
		>;
	};
	i2c2_cap_touch_pins_default: i2c2_cap_touch-default-pins {
		pinctrl-single,pins = <
			AM62X_IOPAD(0x00b0, WKUP_DISABLE|PIN_DEBOUNCE_DISABLE|PIN_DS_FORCE_DISABLE|PIN_INPUT|PIN_DRIVE_STRENGTH_NOMINAL|PIN_DS_ISO_OVERRIDE_DISABLE|PIN_DS_ISO_BYPASS_DISABLE|ACTIVE_STATE_VAL|PIN_DS_INPUT|PIN_SCMITT_TRIGGER_ENABLE, 1) /* (K22) GPMC0_CSn2.I2C2_SCL */
			AM62X_IOPAD(0x00b4, WKUP_DISABLE|PIN_DEBOUNCE_DISABLE|PIN_DS_FORCE_DISABLE|PIN_INPUT|PIN_DRIVE_STRENGTH_NOMINAL|PIN_DS_ISO_OVERRIDE_DISABLE|PIN_DS_ISO_BYPASS_DISABLE|ACTIVE_STATE_VAL|PIN_DS_INPUT|PIN_SCMITT_TRIGGER_ENABLE, 1) /* (K24) GPMC0_CSn3.I2C2_SDA */
		>;
	};
	mdio1_eth_pins_default: mdio1_eth-default-pins {
		pinctrl-single,pins = <
			AM62X_IOPAD(0x0160, WKUP_DISABLE|PIN_DEBOUNCE_DISABLE|PIN_DS_FORCE_DISABLE|PIN_OUTPUT|PIN_DRIVE_STRENGTH_NOMINAL|PIN_DS_ISO_OVERRIDE_DISABLE|PIN_DS_ISO_BYPASS_DISABLE|ACTIVE_STATE_VAL|PIN_DS_INPUT|PIN_SCMITT_TRIGGER_ENABLE, 0) /* (AD24) MDIO0_MDC */
			AM62X_IOPAD(0x015c, WKUP_DISABLE|PIN_DEBOUNCE_DISABLE|PIN_DS_FORCE_DISABLE|PIN_INPUT|PIN_DRIVE_STRENGTH_NOMINAL|PIN_DS_ISO_OVERRIDE_DISABLE|PIN_DS_ISO_BYPASS_DISABLE|ACTIVE_STATE_VAL|PIN_DS_INPUT|PIN_SCMITT_TRIGGER_ENABLE, 0) /* (AB22) MDIO0_MDIO */
		>;
	};
	mmc0_emmc_pins_default: mmc0_emmc-default-pins {
		pinctrl-single,pins = <
			AM62X_IOPAD(0x0218, WKUP_DISABLE|PIN_DEBOUNCE_DISABLE|PIN_DS_FORCE_DISABLE|PIN_OUTPUT|PIN_DRIVE_STRENGTH_NOMINAL|PIN_DS_ISO_OVERRIDE_DISABLE|PIN_DS_ISO_BYPASS_DISABLE|ACTIVE_STATE_VAL|PIN_DS_INPUT|PIN_SCMITT_TRIGGER_ENABLE, 0) /* (AB1) MMC0_CLK */
			AM62X_IOPAD(0x0220, WKUP_DISABLE|PIN_DEBOUNCE_DISABLE|PIN_DS_FORCE_DISABLE|PIN_INPUT_PULLUP|PIN_DRIVE_STRENGTH_NOMINAL|PIN_DS_ISO_OVERRIDE_DISABLE|PIN_DS_ISO_BYPASS_DISABLE|ACTIVE_STATE_VAL|PIN_DS_INPUT|PIN_SCMITT_TRIGGER_ENABLE, 0) /* (Y3) MMC0_CMD */
			AM62X_IOPAD(0x0214, WKUP_DISABLE|PIN_DEBOUNCE_DISABLE|PIN_DS_FORCE_DISABLE|PIN_INPUT_PULLUP|PIN_DRIVE_STRENGTH_NOMINAL|PIN_DS_ISO_OVERRIDE_DISABLE|PIN_DS_ISO_BYPASS_DISABLE|ACTIVE_STATE_VAL|PIN_DS_INPUT|PIN_SCMITT_TRIGGER_ENABLE, 0) /* (AA2) MMC0_DAT0 */
			AM62X_IOPAD(0x0210, WKUP_DISABLE|PIN_DEBOUNCE_DISABLE|PIN_DS_FORCE_DISABLE|PIN_INPUT_PULLUP|PIN_DRIVE_STRENGTH_NOMINAL|PIN_DS_ISO_OVERRIDE_DISABLE|PIN_DS_ISO_BYPASS_DISABLE|ACTIVE_STATE_VAL|PIN_DS_INPUT|PIN_SCMITT_TRIGGER_ENABLE, 0) /* (AA1) MMC0_DAT1 */
			AM62X_IOPAD(0x020c, WKUP_DISABLE|PIN_DEBOUNCE_DISABLE|PIN_DS_FORCE_DISABLE|PIN_INPUT_PULLUP|PIN_DRIVE_STRENGTH_NOMINAL|PIN_DS_ISO_OVERRIDE_DISABLE|PIN_DS_ISO_BYPASS_DISABLE|ACTIVE_STATE_VAL|PIN_DS_INPUT|PIN_SCMITT_TRIGGER_ENABLE, 0) /* (AA3) MMC0_DAT2 */
			AM62X_IOPAD(0x0208, WKUP_DISABLE|PIN_DEBOUNCE_DISABLE|PIN_DS_FORCE_DISABLE|PIN_INPUT_PULLUP|PIN_DRIVE_STRENGTH_NOMINAL|PIN_DS_ISO_OVERRIDE_DISABLE|PIN_DS_ISO_BYPASS_DISABLE|ACTIVE_STATE_VAL|PIN_DS_INPUT|PIN_SCMITT_TRIGGER_ENABLE, 0) /* (Y4) MMC0_DAT3 */
			AM62X_IOPAD(0x0204, WKUP_DISABLE|PIN_DEBOUNCE_DISABLE|PIN_DS_FORCE_DISABLE|PIN_INPUT_PULLUP|PIN_DRIVE_STRENGTH_NOMINAL|PIN_DS_ISO_OVERRIDE_DISABLE|PIN_DS_ISO_BYPASS_DISABLE|ACTIVE_STATE_VAL|PIN_DS_INPUT|PIN_SCMITT_TRIGGER_ENABLE, 0) /* (AB2) MMC0_DAT4 */
			AM62X_IOPAD(0x0200, WKUP_DISABLE|PIN_DEBOUNCE_DISABLE|PIN_DS_FORCE_DISABLE|PIN_INPUT_PULLUP|PIN_DRIVE_STRENGTH_NOMINAL|PIN_DS_ISO_OVERRIDE_DISABLE|PIN_DS_ISO_BYPASS_DISABLE|ACTIVE_STATE_VAL|PIN_DS_INPUT|PIN_SCMITT_TRIGGER_ENABLE, 0) /* (AC1) MMC0_DAT5 */
			AM62X_IOPAD(0x01fc, WKUP_DISABLE|PIN_DEBOUNCE_DISABLE|PIN_DS_FORCE_DISABLE|PIN_INPUT_PULLUP|PIN_DRIVE_STRENGTH_NOMINAL|PIN_DS_ISO_OVERRIDE_DISABLE|PIN_DS_ISO_BYPASS_DISABLE|ACTIVE_STATE_VAL|PIN_DS_INPUT|PIN_SCMITT_TRIGGER_ENABLE, 0) /* (AD2) MMC0_DAT6 */
			AM62X_IOPAD(0x01f8, WKUP_DISABLE|PIN_DEBOUNCE_DISABLE|PIN_DS_FORCE_DISABLE|PIN_INPUT_PULLUP|PIN_DRIVE_STRENGTH_NOMINAL|PIN_DS_ISO_OVERRIDE_DISABLE|PIN_DS_ISO_BYPASS_DISABLE|ACTIVE_STATE_VAL|PIN_DS_INPUT|PIN_SCMITT_TRIGGER_ENABLE, 0) /* (AC2) MMC0_DAT7 */
		>;
	};
	mmc1_micro_sd_pins_default: mmc1_micro_sd-default-pins {
		pinctrl-single,pins = <
			AM62X_IOPAD(0x0234, WKUP_DISABLE|PIN_DEBOUNCE_DISABLE|PIN_DS_FORCE_DISABLE|PIN_OUTPUT|PIN_DRIVE_STRENGTH_NOMINAL|PIN_DS_ISO_OVERRIDE_DISABLE|PIN_DS_ISO_BYPASS_DISABLE|ACTIVE_STATE_VAL|PIN_DS_INPUT|PIN_SCMITT_TRIGGER_ENABLE, 0) /* (B22) MMC1_CLK */
			AM62X_IOPAD(0x023c, WKUP_DISABLE|PIN_DEBOUNCE_DISABLE|PIN_DS_FORCE_DISABLE|PIN_INPUT|PIN_DRIVE_STRENGTH_NOMINAL|PIN_DS_ISO_OVERRIDE_DISABLE|PIN_DS_ISO_BYPASS_DISABLE|ACTIVE_STATE_VAL|PIN_DS_INPUT|PIN_SCMITT_TRIGGER_ENABLE, 0) /* (A21) MMC1_CMD */
			AM62X_IOPAD(0x0230, WKUP_DISABLE|PIN_DEBOUNCE_DISABLE|PIN_DS_FORCE_DISABLE|PIN_INPUT_PULLUP|PIN_DRIVE_STRENGTH_NOMINAL|PIN_DS_ISO_OVERRIDE_DISABLE|PIN_DS_ISO_BYPASS_DISABLE|ACTIVE_STATE_VAL|PIN_DS_INPUT|PIN_SCMITT_TRIGGER_ENABLE, 0) /* (A22) MMC1_DAT0 */
			AM62X_IOPAD(0x022c, WKUP_DISABLE|PIN_DEBOUNCE_DISABLE|PIN_DS_FORCE_DISABLE|PIN_INPUT_PULLUP|PIN_DRIVE_STRENGTH_NOMINAL|PIN_DS_ISO_OVERRIDE_DISABLE|PIN_DS_ISO_BYPASS_DISABLE|ACTIVE_STATE_VAL|PIN_DS_INPUT|PIN_SCMITT_TRIGGER_ENABLE, 0) /* (B21) MMC1_DAT1 */
			AM62X_IOPAD(0x0228, WKUP_DISABLE|PIN_DEBOUNCE_DISABLE|PIN_DS_FORCE_DISABLE|PIN_INPUT_PULLUP|PIN_DRIVE_STRENGTH_NOMINAL|PIN_DS_ISO_OVERRIDE_DISABLE|PIN_DS_ISO_BYPASS_DISABLE|ACTIVE_STATE_VAL|PIN_DS_INPUT|PIN_SCMITT_TRIGGER_ENABLE, 0) /* (C21) MMC1_DAT2 */
			AM62X_IOPAD(0x0224, WKUP_DISABLE|PIN_DEBOUNCE_DISABLE|PIN_DS_FORCE_DISABLE|PIN_INPUT_PULLUP|PIN_DRIVE_STRENGTH_NOMINAL|PIN_DS_ISO_OVERRIDE_DISABLE|PIN_DS_ISO_BYPASS_DISABLE|ACTIVE_STATE_VAL|PIN_DS_INPUT|PIN_SCMITT_TRIGGER_ENABLE, 0) /* (D22) MMC1_DAT3 */
			AM62X_IOPAD(0x0240, WKUP_DISABLE|PIN_DEBOUNCE_DISABLE|PIN_DS_FORCE_DISABLE|PIN_INPUT|PIN_DRIVE_STRENGTH_NOMINAL|PIN_DS_ISO_OVERRIDE_DISABLE|PIN_DS_ISO_BYPASS_DISABLE|ACTIVE_STATE_VAL|PIN_DS_INPUT|PIN_SCMITT_TRIGGER_ENABLE, 0) /* (D17) MMC1_SDCD */
			AM62X_IOPAD(0x0244, WKUP_DISABLE|PIN_DEBOUNCE_DISABLE|PIN_DS_FORCE_DISABLE|PIN_INPUT|PIN_DRIVE_STRENGTH_NOMINAL|PIN_DS_ISO_OVERRIDE_DISABLE|PIN_DS_ISO_BYPASS_DISABLE|ACTIVE_STATE_VAL|PIN_DS_INPUT|PIN_SCMITT_TRIGGER_ENABLE, 0) /* (C17) MMC1_SDWP */
		>;
	};
	mmc2_unused_wifi_pins_default: mmc2_unused_wifi-default-pins {
		pinctrl-single,pins = <
			AM62X_IOPAD(0x0118, WKUP_DISABLE|PIN_DEBOUNCE_DISABLE|PIN_DS_FORCE_DISABLE|PIN_OUTPUT|PIN_DRIVE_STRENGTH_NOMINAL|PIN_DS_ISO_OVERRIDE_DISABLE|PIN_DS_ISO_BYPASS_DISABLE|ACTIVE_STATE_VAL|PIN_DS_INPUT|PIN_SCMITT_TRIGGER_ENABLE, 0) /* (D25) MMC2_CLK */
			AM62X_IOPAD(0x011C, WKUP_DISABLE|PIN_DEBOUNCE_DISABLE|PIN_DS_FORCE_DISABLE|PIN_SCMITT_TRIGGER_ENABLE|PIN_INPUT|PIN_DRIVE_STRENGTH_NOMINAL|PIN_DS_ISO_OVERRIDE_DISABLE|PIN_DS_ISO_BYPASS_DISABLE|ACTIVE_STATE_VAL|PIN_DS_INPUT, 0) /* (N/A) MMC2_CLKLB */ 
			AM62X_IOPAD(0x0120, WKUP_DISABLE|PIN_DEBOUNCE_DISABLE|PIN_DS_FORCE_DISABLE|PIN_INPUT|PIN_DRIVE_STRENGTH_NOMINAL|PIN_DS_ISO_OVERRIDE_DISABLE|PIN_DS_ISO_BYPASS_DISABLE|ACTIVE_STATE_VAL|PIN_DS_INPUT|PIN_SCMITT_TRIGGER_ENABLE, 0) /* (C24) MMC2_CMD */
			AM62X_IOPAD(0x0114, WKUP_DISABLE|PIN_DEBOUNCE_DISABLE|PIN_DS_FORCE_DISABLE|PIN_INPUT|PIN_DRIVE_STRENGTH_NOMINAL|PIN_DS_ISO_OVERRIDE_DISABLE|PIN_DS_ISO_BYPASS_DISABLE|ACTIVE_STATE_VAL|PIN_DS_INPUT|PIN_SCMITT_TRIGGER_ENABLE, 0) /* (B24) MMC2_DAT0 */
			AM62X_IOPAD(0x0110, WKUP_DISABLE|PIN_DEBOUNCE_DISABLE|PIN_DS_FORCE_DISABLE|PIN_INPUT|PIN_DRIVE_STRENGTH_NOMINAL|PIN_DS_ISO_OVERRIDE_DISABLE|PIN_DS_ISO_BYPASS_DISABLE|ACTIVE_STATE_VAL|PIN_DS_INPUT|PIN_SCMITT_TRIGGER_ENABLE, 0) /* (C25) MMC2_DAT1 */
			AM62X_IOPAD(0x010c, WKUP_DISABLE|PIN_DEBOUNCE_DISABLE|PIN_DS_FORCE_DISABLE|PIN_INPUT|PIN_DRIVE_STRENGTH_NOMINAL|PIN_DS_ISO_OVERRIDE_DISABLE|PIN_DS_ISO_BYPASS_DISABLE|ACTIVE_STATE_VAL|PIN_DS_INPUT|PIN_SCMITT_TRIGGER_ENABLE, 0) /* (E23) MMC2_DAT2 */
			AM62X_IOPAD(0x0108, WKUP_DISABLE|PIN_DEBOUNCE_DISABLE|PIN_DS_FORCE_DISABLE|PIN_INPUT|PIN_DRIVE_STRENGTH_NOMINAL|PIN_DS_ISO_OVERRIDE_DISABLE|PIN_DS_ISO_BYPASS_DISABLE|ACTIVE_STATE_VAL|PIN_DS_INPUT|PIN_SCMITT_TRIGGER_ENABLE, 0) /* (D24) MMC2_DAT3 */
			AM62X_IOPAD(0x0124, WKUP_DISABLE|PIN_DEBOUNCE_DISABLE|PIN_DS_FORCE_DISABLE|PIN_INPUT|PIN_DRIVE_STRENGTH_NOMINAL|PIN_DS_ISO_OVERRIDE_DISABLE|PIN_DS_ISO_BYPASS_DISABLE|ACTIVE_STATE_VAL|PIN_DS_INPUT|PIN_SCMITT_TRIGGER_ENABLE, 0) /* (A23) MMC2_SDCD */
			AM62X_IOPAD(0x0128, WKUP_DISABLE|PIN_DEBOUNCE_DISABLE|PIN_DS_FORCE_DISABLE|PIN_INPUT|PIN_DRIVE_STRENGTH_NOMINAL|PIN_DS_ISO_OVERRIDE_DISABLE|PIN_DS_ISO_BYPASS_DISABLE|ACTIVE_STATE_VAL|PIN_DS_INPUT|PIN_SCMITT_TRIGGER_ENABLE, 0) /* (B23) MMC2_SDWP */
		>;
	};
	rgmii1_eth_pins_default: rgmii1_eth-default-pins {
		pinctrl-single,pins = <
			AM62X_IOPAD(0x014c, WKUP_DISABLE|PIN_DEBOUNCE_DISABLE|PIN_DS_FORCE_DISABLE|PIN_INPUT|PIN_DRIVE_STRENGTH_NOMINAL|PIN_DS_ISO_OVERRIDE_DISABLE|PIN_DS_ISO_BYPASS_DISABLE|ACTIVE_STATE_VAL|PIN_DS_INPUT|PIN_SCMITT_TRIGGER_ENABLE, 0) /* (AB17) RGMII1_RD0 */
			AM62X_IOPAD(0x0150, WKUP_DISABLE|PIN_DEBOUNCE_DISABLE|PIN_DS_FORCE_DISABLE|PIN_INPUT|PIN_DRIVE_STRENGTH_NOMINAL|PIN_DS_ISO_OVERRIDE_DISABLE|PIN_DS_ISO_BYPASS_DISABLE|ACTIVE_STATE_VAL|PIN_DS_INPUT|PIN_SCMITT_TRIGGER_ENABLE, 0) /* (AC17) RGMII1_RD1 */
			AM62X_IOPAD(0x0154, WKUP_DISABLE|PIN_DEBOUNCE_DISABLE|PIN_DS_FORCE_DISABLE|PIN_INPUT|PIN_DRIVE_STRENGTH_NOMINAL|PIN_DS_ISO_OVERRIDE_DISABLE|PIN_DS_ISO_BYPASS_DISABLE|ACTIVE_STATE_VAL|PIN_DS_INPUT|PIN_SCMITT_TRIGGER_ENABLE, 0) /* (AB16) RGMII1_RD2 */
			AM62X_IOPAD(0x0158, WKUP_DISABLE|PIN_DEBOUNCE_DISABLE|PIN_DS_FORCE_DISABLE|PIN_INPUT|PIN_DRIVE_STRENGTH_NOMINAL|PIN_DS_ISO_OVERRIDE_DISABLE|PIN_DS_ISO_BYPASS_DISABLE|ACTIVE_STATE_VAL|PIN_DS_INPUT|PIN_SCMITT_TRIGGER_ENABLE, 0) /* (AA15) RGMII1_RD3 */
			AM62X_IOPAD(0x0148, WKUP_DISABLE|PIN_DEBOUNCE_DISABLE|PIN_DS_FORCE_DISABLE|PIN_INPUT|PIN_DRIVE_STRENGTH_NOMINAL|PIN_DS_ISO_OVERRIDE_DISABLE|PIN_DS_ISO_BYPASS_DISABLE|ACTIVE_STATE_VAL|PIN_DS_INPUT|PIN_SCMITT_TRIGGER_ENABLE, 0) /* (AD17) RGMII1_RXC */
			AM62X_IOPAD(0x0144, WKUP_DISABLE|PIN_DEBOUNCE_DISABLE|PIN_DS_FORCE_DISABLE|PIN_INPUT|PIN_DRIVE_STRENGTH_NOMINAL|PIN_DS_ISO_OVERRIDE_DISABLE|PIN_DS_ISO_BYPASS_DISABLE|ACTIVE_STATE_VAL|PIN_DS_INPUT|PIN_SCMITT_TRIGGER_ENABLE, 0) /* (AE17) RGMII1_RX_CTL */
			AM62X_IOPAD(0x0134, WKUP_DISABLE|PIN_DEBOUNCE_DISABLE|PIN_DS_FORCE_DISABLE|PIN_OUTPUT|PIN_DRIVE_STRENGTH_NOMINAL|PIN_DS_ISO_OVERRIDE_DISABLE|PIN_DS_ISO_BYPASS_DISABLE|ACTIVE_STATE_VAL|PIN_DS_INPUT|PIN_SCMITT_TRIGGER_ENABLE, 0) /* (AE20) RGMII1_TD0 */
			AM62X_IOPAD(0x0138, WKUP_DISABLE|PIN_DEBOUNCE_DISABLE|PIN_DS_FORCE_DISABLE|PIN_OUTPUT|PIN_DRIVE_STRENGTH_NOMINAL|PIN_DS_ISO_OVERRIDE_DISABLE|PIN_DS_ISO_BYPASS_DISABLE|ACTIVE_STATE_VAL|PIN_DS_INPUT|PIN_SCMITT_TRIGGER_ENABLE, 0) /* (AD20) RGMII1_TD1 */
			AM62X_IOPAD(0x013c, WKUP_DISABLE|PIN_DEBOUNCE_DISABLE|PIN_DS_FORCE_DISABLE|PIN_OUTPUT|PIN_DRIVE_STRENGTH_NOMINAL|PIN_DS_ISO_OVERRIDE_DISABLE|PIN_DS_ISO_BYPASS_DISABLE|ACTIVE_STATE_VAL|PIN_DS_INPUT|PIN_SCMITT_TRIGGER_ENABLE, 0) /* (AE18) RGMII1_TD2 */
			AM62X_IOPAD(0x0140, WKUP_DISABLE|PIN_DEBOUNCE_DISABLE|PIN_DS_FORCE_DISABLE|PIN_OUTPUT|PIN_DRIVE_STRENGTH_NOMINAL|PIN_DS_ISO_OVERRIDE_DISABLE|PIN_DS_ISO_BYPASS_DISABLE|ACTIVE_STATE_VAL|PIN_DS_INPUT|PIN_SCMITT_TRIGGER_ENABLE, 0) /* (AD18) RGMII1_TD3 */
			AM62X_IOPAD(0x0130, WKUP_DISABLE|PIN_DEBOUNCE_DISABLE|PIN_DS_FORCE_DISABLE|PIN_OUTPUT|PIN_DRIVE_STRENGTH_NOMINAL|PIN_DS_ISO_OVERRIDE_DISABLE|PIN_DS_ISO_BYPASS_DISABLE|ACTIVE_STATE_VAL|PIN_DS_INPUT|PIN_SCMITT_TRIGGER_ENABLE, 0) /* (AE19) RGMII1_TXC */
			AM62X_IOPAD(0x012c, WKUP_DISABLE|PIN_DEBOUNCE_DISABLE|PIN_DS_FORCE_DISABLE|PIN_OUTPUT|PIN_DRIVE_STRENGTH_NOMINAL|PIN_DS_ISO_OVERRIDE_DISABLE|PIN_DS_ISO_BYPASS_DISABLE|ACTIVE_STATE_VAL|PIN_DS_INPUT|PIN_SCMITT_TRIGGER_ENABLE, 0) /* (AD19) RGMII1_TX_CTL */
		>;
	};
	spi1_tft_pins_default: spi1_tft-default-pins {
		pinctrl-single,pins = <
			AM62X_IOPAD(0x0020, WKUP_DISABLE|PIN_DEBOUNCE_DISABLE|PIN_DS_FORCE_DISABLE|PIN_OUTPUT|PIN_DRIVE_STRENGTH_NOMINAL|PIN_DS_ISO_OVERRIDE_DISABLE|PIN_DS_ISO_BYPASS_DISABLE|ACTIVE_STATE_VAL|PIN_DS_INPUT|PIN_SCMITT_TRIGGER_ENABLE, 1) /* (J25) OSPI0_D5.SPI1_CLK */
			AM62X_IOPAD(0x001c, WKUP_DISABLE|PIN_DEBOUNCE_DISABLE|PIN_DS_FORCE_DISABLE|PIN_OUTPUT|PIN_DRIVE_STRENGTH_NOMINAL|PIN_DS_ISO_OVERRIDE_DISABLE|PIN_DS_ISO_BYPASS_DISABLE|ACTIVE_STATE_VAL|PIN_DS_INPUT|PIN_SCMITT_TRIGGER_ENABLE, 1) /* (J23) OSPI0_D4.SPI1_CS0 */
			AM62X_IOPAD(0x0024, WKUP_DISABLE|PIN_DEBOUNCE_DISABLE|PIN_DS_FORCE_DISABLE|PIN_INPUT|PIN_DRIVE_STRENGTH_NOMINAL|PIN_DS_ISO_OVERRIDE_DISABLE|PIN_DS_ISO_BYPASS_DISABLE|ACTIVE_STATE_VAL|PIN_DS_INPUT|PIN_SCMITT_TRIGGER_ENABLE, 1) /* (H25) OSPI0_D6.SPI1_D0 */
		>;
	};
	system1_pins_default: system1-default-pins {
		pinctrl-single,pins = <
			AM62X_IOPAD(0x01f4, WKUP_DISABLE|PIN_DEBOUNCE_DISABLE|PIN_DS_FORCE_DISABLE|PIN_INPUT|PIN_DRIVE_STRENGTH_NOMINAL|PIN_DS_ISO_OVERRIDE_DISABLE|PIN_DS_ISO_BYPASS_DISABLE|ACTIVE_STATE_VAL|PIN_DS_INPUT|PIN_SCMITT_TRIGGER_ENABLE, 0) /* (D16) EXTINTn */
			AM62X_IOPAD(0x01f0, WKUP_DISABLE|PIN_DEBOUNCE_DISABLE|PIN_DS_FORCE_DISABLE|PIN_INPUT|PIN_DRIVE_STRENGTH_NOMINAL|PIN_DS_ISO_OVERRIDE_DISABLE|PIN_DS_ISO_BYPASS_DISABLE|ACTIVE_STATE_VAL|PIN_DS_INPUT|PIN_SCMITT_TRIGGER_ENABLE, 0) /* (A18) EXT_REFCLK1 */
			AM62X_IOPAD(0x0250, WKUP_DISABLE|PIN_DEBOUNCE_DISABLE|PIN_DS_FORCE_DISABLE|PIN_OUTPUT|PIN_DRIVE_STRENGTH_NOMINAL|PIN_DS_ISO_OVERRIDE_DISABLE|PIN_DS_ISO_BYPASS_DISABLE|ACTIVE_STATE_VAL|PIN_DS_INPUT|PIN_SCMITT_TRIGGER_ENABLE, 0) /* (E21) PORz_OUT */
			AM62X_IOPAD(0x024c, WKUP_DISABLE|PIN_DEBOUNCE_DISABLE|PIN_DS_FORCE_DISABLE|PIN_OUTPUT|PIN_DRIVE_STRENGTH_NOMINAL|PIN_DS_ISO_OVERRIDE_DISABLE|PIN_DS_ISO_BYPASS_DISABLE|ACTIVE_STATE_VAL|PIN_DS_INPUT|PIN_SCMITT_TRIGGER_ENABLE, 0) /* (F22) RESETSTATz */
			AM62X_IOPAD(0x0248, WKUP_DISABLE|PIN_DEBOUNCE_DISABLE|PIN_DS_FORCE_DISABLE|PIN_INPUT_PULLUP|PIN_DRIVE_STRENGTH_NOMINAL|PIN_DS_ISO_OVERRIDE_DISABLE|PIN_DS_ISO_BYPASS_DISABLE|ACTIVE_STATE_VAL|PIN_DS_INPUT|PIN_SCMITT_TRIGGER_ENABLE, 0) /* (F20) RESET_REQz */
		>;
	};
	uart1_bt_uart_pins_default: uart1_bt_uart-default-pins {
		pinctrl-single,pins = <
			AM62X_IOPAD(0x0194, WKUP_DISABLE|PIN_DEBOUNCE_DISABLE|PIN_DS_FORCE_DISABLE|PIN_INPUT|PIN_DRIVE_STRENGTH_NOMINAL|PIN_DS_ISO_OVERRIDE_DISABLE|PIN_DS_ISO_BYPASS_DISABLE|ACTIVE_STATE_VAL|PIN_DS_INPUT|PIN_SCMITT_TRIGGER_ENABLE, 2) /* (B19) MCASP0_AXR3.UART1_CTSn */
			AM62X_IOPAD(0x0198, WKUP_DISABLE|PIN_DEBOUNCE_DISABLE|PIN_DS_FORCE_DISABLE|PIN_OUTPUT|PIN_DRIVE_STRENGTH_NOMINAL|PIN_DS_ISO_OVERRIDE_DISABLE|PIN_DS_ISO_BYPASS_DISABLE|ACTIVE_STATE_VAL|PIN_DS_INPUT|PIN_SCMITT_TRIGGER_ENABLE, 2) /* (A19) MCASP0_AXR2.UART1_RTSn */
			AM62X_IOPAD(0x01e8, WKUP_DISABLE|PIN_DEBOUNCE_DISABLE|PIN_DS_FORCE_DISABLE|PIN_INPUT|PIN_DRIVE_STRENGTH_NOMINAL|PIN_DS_ISO_OVERRIDE_DISABLE|PIN_DS_ISO_BYPASS_DISABLE|ACTIVE_STATE_VAL|PIN_DS_INPUT|PIN_SCMITT_TRIGGER_ENABLE, 1) /* (B17) I2C1_SCL.UART1_RXD */
			AM62X_IOPAD(0x01ec, WKUP_DISABLE|PIN_DEBOUNCE_DISABLE|PIN_DS_FORCE_DISABLE|PIN_OUTPUT|PIN_DRIVE_STRENGTH_NOMINAL|PIN_DS_ISO_OVERRIDE_DISABLE|PIN_DS_ISO_BYPASS_DISABLE|ACTIVE_STATE_VAL|PIN_DS_INPUT|PIN_SCMITT_TRIGGER_ENABLE, 1) /* (A17) I2C1_SDA.UART1_TXD */
		>;
	};
	uart6_dante_uart_pins_default: uart6_dante_uart-default-pins {
		pinctrl-single,pins = <
			AM62X_IOPAD(0x009c, WKUP_DISABLE|PIN_DEBOUNCE_DISABLE|PIN_DS_FORCE_DISABLE|PIN_INPUT|PIN_DRIVE_STRENGTH_NOMINAL|PIN_DS_ISO_OVERRIDE_DISABLE|PIN_DS_ISO_BYPASS_DISABLE|ACTIVE_STATE_VAL|PIN_DS_INPUT|PIN_SCMITT_TRIGGER_ENABLE, 3) /* (V25) GPMC0_WAIT1.UART6_RXD */
			AM62X_IOPAD(0x00a0, WKUP_DISABLE|PIN_DEBOUNCE_DISABLE|PIN_DS_FORCE_DISABLE|PIN_OUTPUT|PIN_DRIVE_STRENGTH_NOMINAL|PIN_DS_ISO_OVERRIDE_DISABLE|PIN_DS_ISO_BYPASS_DISABLE|ACTIVE_STATE_VAL|PIN_DS_INPUT|PIN_SCMITT_TRIGGER_ENABLE, 3) /* (K25) GPMC0_WPn.UART6_TXD */
		>;
	};
	uart1_uart_debug_pins_default: uart1_uart_debug-default-pins {
		pinctrl-single,pins = <
			AM62X_IOPAD(0x01c8, WKUP_DISABLE|PIN_DEBOUNCE_DISABLE|PIN_DS_FORCE_DISABLE|PIN_INPUT|PIN_DRIVE_STRENGTH_NOMINAL|PIN_DS_ISO_OVERRIDE_DISABLE|PIN_DS_ISO_BYPASS_DISABLE|ACTIVE_STATE_VAL|PIN_DS_INPUT|PIN_SCMITT_TRIGGER_ENABLE, 0) /* (D14) UART0_RXD */
			AM62X_IOPAD(0x01cc, WKUP_DISABLE|PIN_DEBOUNCE_DISABLE|PIN_DS_FORCE_DISABLE|PIN_OUTPUT|PIN_DRIVE_STRENGTH_NOMINAL|PIN_DS_ISO_OVERRIDE_DISABLE|PIN_DS_ISO_BYPASS_DISABLE|ACTIVE_STATE_VAL|PIN_DS_INPUT|PIN_SCMITT_TRIGGER_ENABLE, 0) /* (E14) UART0_TXD */
		>;
	};
	usb0_pins_default: usb0-default-pins {
		pinctrl-single,pins = <
			AM62X_IOPAD(0x0254, WKUP_DISABLE|PIN_DEBOUNCE_DISABLE|PIN_DS_FORCE_DISABLE|PIN_OUTPUT|PIN_DRIVE_STRENGTH_NOMINAL|PIN_DS_ISO_OVERRIDE_DISABLE|PIN_DS_ISO_BYPASS_DISABLE|ACTIVE_STATE_VAL|PIN_DS_INPUT|PIN_SCMITT_TRIGGER_ENABLE, 0) /* (C20) USB0_DRVVBUS */
		>;
	};
	usb1_extra_pins_default: usb1_extra-default-pins {
		pinctrl-single,pins = <
			AM62X_IOPAD(0x0258, WKUP_DISABLE|PIN_DEBOUNCE_DISABLE|PIN_DS_FORCE_DISABLE|PIN_OUTPUT|PIN_DRIVE_STRENGTH_NOMINAL|PIN_DS_ISO_OVERRIDE_DISABLE|PIN_DS_ISO_BYPASS_DISABLE|ACTIVE_STATE_VAL|PIN_DS_INPUT|PIN_SCMITT_TRIGGER_ENABLE, 0) /* (F18) USB1_DRVVBUS */
		>;
	};
	mcasp0_pins_default: mcasp0-default-pins {
		pinctrl-single,pins = <
			AM62X_IOPAD(0x01a4, WKUP_DISABLE|PIN_DEBOUNCE_DISABLE|PIN_DS_FORCE_DISABLE|PIN_INPUT|PIN_DRIVE_STRENGTH_NOMINAL|PIN_DS_ISO_OVERRIDE_DISABLE|PIN_DS_ISO_BYPASS_DISABLE|ACTIVE_STATE_VAL|PIN_DS_INPUT|PIN_SCMITT_TRIGGER_ENABLE, 0) /* (B20) MCASP0_ACLKX */
			AM62X_IOPAD(0x01a8, WKUP_DISABLE|PIN_DEBOUNCE_DISABLE|PIN_DS_FORCE_DISABLE|PIN_INPUT|PIN_DRIVE_STRENGTH_NOMINAL|PIN_DS_ISO_OVERRIDE_DISABLE|PIN_DS_ISO_BYPASS_DISABLE|ACTIVE_STATE_VAL|PIN_DS_INPUT|PIN_SCMITT_TRIGGER_ENABLE, 0) /* (D20) MCASP0_AFSX */
			AM62X_IOPAD(0x01b0, WKUP_DISABLE|PIN_DEBOUNCE_DISABLE|PIN_DS_FORCE_DISABLE|PIN_INPUT|PIN_DRIVE_STRENGTH_NOMINAL|PIN_DS_ISO_OVERRIDE_DISABLE|PIN_DS_ISO_BYPASS_DISABLE|ACTIVE_STATE_VAL|PIN_DS_INPUT|PIN_SCMITT_TRIGGER_ENABLE, 0) /* (A20) MCASP0_ACLKR */
			AM62X_IOPAD(0x01ac, WKUP_DISABLE|PIN_DEBOUNCE_DISABLE|PIN_DS_FORCE_DISABLE|PIN_INPUT|PIN_DRIVE_STRENGTH_NOMINAL|PIN_DS_ISO_OVERRIDE_DISABLE|PIN_DS_ISO_BYPASS_DISABLE|ACTIVE_STATE_VAL|PIN_DS_INPUT|PIN_SCMITT_TRIGGER_ENABLE, 0) /* (E19) MCASP0_AFSR */
			AM62X_IOPAD(0x019c, WKUP_DISABLE|PIN_DEBOUNCE_DISABLE|PIN_DS_FORCE_DISABLE|PIN_INPUT|PIN_DRIVE_STRENGTH_NOMINAL|PIN_DS_ISO_OVERRIDE_DISABLE|PIN_DS_ISO_BYPASS_DISABLE|ACTIVE_STATE_VAL|PIN_DS_INPUT|PIN_SCMITT_TRIGGER_ENABLE, 0) /* (B18) MCASP0_AXR1 */
			AM62X_IOPAD(0x01a0, WKUP_DISABLE|PIN_DEBOUNCE_DISABLE|PIN_DS_FORCE_DISABLE|PIN_INPUT|PIN_DRIVE_STRENGTH_NOMINAL|PIN_DS_ISO_OVERRIDE_DISABLE|PIN_DS_ISO_BYPASS_DISABLE|ACTIVE_STATE_VAL|PIN_DS_INPUT|PIN_SCMITT_TRIGGER_ENABLE, 0) /* (E18) MCASP0_AXR0 */
		>;
	};
};

&mcu_pmx0 {
	jtag1_pins_default: jtag1-default-pins {
		pinctrl-single,pins = <
			AM62X_MCU_IOPAD(0x0078, WKUP_DISABLE|PIN_DEBOUNCE_DISABLE|PIN_DS_FORCE_DISABLE|PIN_INPUT_PULLUP|PIN_DRIVE_STRENGTH_NOMINAL|PIN_DS_ISO_OVERRIDE_DISABLE|PIN_DS_ISO_BYPASS_DISABLE|ACTIVE_STATE_VAL|PIN_DS_INPUT|PIN_SCMITT_TRIGGER_ENABLE, 0) /* (E12) EMU0 */
			AM62X_MCU_IOPAD(0x007c, WKUP_DISABLE|PIN_DEBOUNCE_DISABLE|PIN_DS_FORCE_DISABLE|PIN_INPUT_PULLUP|PIN_DRIVE_STRENGTH_NOMINAL|PIN_DS_ISO_OVERRIDE_DISABLE|PIN_DS_ISO_BYPASS_DISABLE|ACTIVE_STATE_VAL|PIN_DS_INPUT|PIN_SCMITT_TRIGGER_ENABLE, 0) /* (C11) EMU1 */
			AM62X_MCU_IOPAD(0x0064, WKUP_DISABLE|PIN_DEBOUNCE_DISABLE|PIN_DS_FORCE_DISABLE|PIN_INPUT_PULLUP|PIN_DRIVE_STRENGTH_NOMINAL|PIN_DS_ISO_OVERRIDE_DISABLE|PIN_DS_ISO_BYPASS_DISABLE|ACTIVE_STATE_VAL|PIN_DS_INPUT|PIN_SCMITT_TRIGGER_ENABLE, 0) /* (A10) TCK */
			AM62X_MCU_IOPAD(0x006c, WKUP_DISABLE|PIN_DEBOUNCE_DISABLE|PIN_DS_FORCE_DISABLE|PIN_INPUT_PULLUP|PIN_DRIVE_STRENGTH_NOMINAL|PIN_DS_ISO_OVERRIDE_DISABLE|PIN_DS_ISO_BYPASS_DISABLE|ACTIVE_STATE_VAL|PIN_DS_INPUT|PIN_SCMITT_TRIGGER_ENABLE, 0) /* (A11) TDI */
			AM62X_MCU_IOPAD(0x0070, WKUP_DISABLE|PIN_DEBOUNCE_DISABLE|PIN_DS_FORCE_DISABLE|PIN_OUTPUT_PULLUP|PIN_DRIVE_STRENGTH_NOMINAL|PIN_DS_ISO_OVERRIDE_DISABLE|PIN_DS_ISO_BYPASS_DISABLE|ACTIVE_STATE_VAL|PIN_DS_INPUT|PIN_SCMITT_TRIGGER_ENABLE, 0) /* (D12) TDO */
			AM62X_MCU_IOPAD(0x0074, WKUP_DISABLE|PIN_DEBOUNCE_DISABLE|PIN_DS_FORCE_DISABLE|PIN_INPUT_PULLUP|PIN_DRIVE_STRENGTH_NOMINAL|PIN_DS_ISO_OVERRIDE_DISABLE|PIN_DS_ISO_BYPASS_DISABLE|ACTIVE_STATE_VAL|PIN_DS_INPUT|PIN_SCMITT_TRIGGER_ENABLE, 0) /* (B11) TMS */
			AM62X_MCU_IOPAD(0x0068, WKUP_DISABLE|PIN_DEBOUNCE_DISABLE|PIN_DS_FORCE_DISABLE|PIN_INPUT_PULLDOWN|PIN_DRIVE_STRENGTH_NOMINAL|PIN_DS_ISO_OVERRIDE_DISABLE|PIN_DS_ISO_BYPASS_DISABLE|ACTIVE_STATE_VAL|PIN_DS_INPUT|PIN_SCMITT_TRIGGER_ENABLE, 0) /* (B10) TRSTn */
		>;
	};
	mcu_i2c0_unused_pins_default: mcu_i2c0_unused-default-pins {
		pinctrl-single,pins = <
			AM62X_MCU_IOPAD(0x0044, WKUP_DISABLE|PIN_DEBOUNCE_DISABLE|PIN_DS_FORCE_DISABLE|PIN_INPUT|PIN_DRIVE_STRENGTH_NOMINAL|PIN_DS_ISO_OVERRIDE_DISABLE|PIN_DS_ISO_BYPASS_DISABLE|ACTIVE_STATE_VAL|PIN_DS_INPUT|PIN_SCMITT_TRIGGER_ENABLE, 0) /* (A8) MCU_I2C0_SCL */
			AM62X_MCU_IOPAD(0x0048, WKUP_DISABLE|PIN_DEBOUNCE_DISABLE|PIN_DS_FORCE_DISABLE|PIN_INPUT|PIN_DRIVE_STRENGTH_NOMINAL|PIN_DS_ISO_OVERRIDE_DISABLE|PIN_DS_ISO_BYPASS_DISABLE|ACTIVE_STATE_VAL|PIN_DS_INPUT|PIN_SCMITT_TRIGGER_ENABLE, 0) /* (D10) MCU_I2C0_SDA */
		>;
	};
	mcu_spi1_adc_pins_default: mcu_spi1_adc-default-pins {
		pinctrl-single,pins = <
			AM62X_MCU_IOPAD(0x0008, WKUP_DISABLE|PIN_DEBOUNCE_DISABLE|PIN_DS_FORCE_DISABLE|PIN_INPUT|PIN_DRIVE_STRENGTH_NOMINAL|PIN_DS_ISO_OVERRIDE_DISABLE|PIN_DS_ISO_BYPASS_DISABLE|ACTIVE_STATE_VAL|PIN_DS_INPUT|PIN_SCMITT_TRIGGER_ENABLE, 0) /* (A7) MCU_SPI0_CLK */
			AM62X_MCU_IOPAD(0x0000, WKUP_DISABLE|PIN_DEBOUNCE_DISABLE|PIN_DS_FORCE_DISABLE|PIN_OUTPUT|PIN_DRIVE_STRENGTH_NOMINAL|PIN_DS_ISO_OVERRIDE_DISABLE|PIN_DS_ISO_BYPASS_DISABLE|ACTIVE_STATE_VAL|PIN_DS_INPUT|PIN_SCMITT_TRIGGER_ENABLE, 0) /* (E8) MCU_SPI0_CS0 */
			AM62X_MCU_IOPAD(0x000c, WKUP_DISABLE|PIN_DEBOUNCE_DISABLE|PIN_DS_FORCE_DISABLE|PIN_OUTPUT|PIN_DRIVE_STRENGTH_NOMINAL|PIN_DS_ISO_OVERRIDE_DISABLE|PIN_DS_ISO_BYPASS_DISABLE|ACTIVE_STATE_VAL|PIN_DS_INPUT|PIN_SCMITT_TRIGGER_ENABLE, 0) /* (D9) MCU_SPI0_D0 */
			AM62X_MCU_IOPAD(0x0010, WKUP_DISABLE|PIN_DEBOUNCE_DISABLE|PIN_DS_FORCE_DISABLE|PIN_INPUT|PIN_DRIVE_STRENGTH_NOMINAL|PIN_DS_ISO_OVERRIDE_DISABLE|PIN_DS_ISO_BYPASS_DISABLE|ACTIVE_STATE_VAL|PIN_DS_INPUT|PIN_SCMITT_TRIGGER_ENABLE, 0) /* (C9) MCU_SPI0_D1 */
		>;
	};
	mcu_system1_pins_default: mcu_system1-default-pins {
		pinctrl-single,pins = <
			AM62X_MCU_IOPAD(0x0060, WKUP_DISABLE|PIN_DEBOUNCE_DISABLE|PIN_DS_FORCE_DISABLE|PIN_INPUT_PULLDOWN|PIN_DRIVE_STRENGTH_NOMINAL|PIN_DS_ISO_OVERRIDE_DISABLE|PIN_DS_ISO_BYPASS_DISABLE|ACTIVE_STATE_VAL|PIN_DS_INPUT|PIN_SCMITT_TRIGGER_ENABLE, 0) /* (D1) MCU_ERRORn */
			AM62X_MCU_IOPAD(0x003c, WKUP_DISABLE|PIN_DEBOUNCE_DISABLE|PIN_DS_FORCE_DISABLE|PIN_INPUT|PIN_DRIVE_STRENGTH_NOMINAL|PIN_DS_ISO_OVERRIDE_DISABLE|PIN_DS_ISO_BYPASS_DISABLE|ACTIVE_STATE_VAL|PIN_DS_INPUT|PIN_SCMITT_TRIGGER_ENABLE, 4) /* (E5) MCU_MCAN1_TX.MCU_EXT_REFCLK0 */
			AM62X_MCU_IOPAD(0x0004, WKUP_DISABLE|PIN_DEBOUNCE_DISABLE|PIN_DS_FORCE_DISABLE|PIN_OUTPUT|PIN_DRIVE_STRENGTH_NOMINAL|PIN_DS_ISO_OVERRIDE_DISABLE|PIN_DS_ISO_BYPASS_DISABLE|ACTIVE_STATE_VAL|PIN_DS_INPUT|PIN_SCMITT_TRIGGER_ENABLE, 1) /* (B8) MCU_SPI0_CS1.MCU_OBSCLK0 */
			AM62X_MCU_IOPAD(0x0058, WKUP_DISABLE|PIN_DEBOUNCE_DISABLE|PIN_DS_FORCE_DISABLE|PIN_OUTPUT|PIN_DRIVE_STRENGTH_NOMINAL|PIN_DS_ISO_OVERRIDE_DISABLE|PIN_DS_ISO_BYPASS_DISABLE|ACTIVE_STATE_VAL|PIN_DS_INPUT|PIN_SCMITT_TRIGGER_ENABLE, 0) /* (D2) MCU_PORz */
			AM62X_MCU_IOPAD(0x005c, WKUP_DISABLE|PIN_DEBOUNCE_DISABLE|PIN_DS_FORCE_DISABLE|PIN_OUTPUT|PIN_DRIVE_STRENGTH_NOMINAL|PIN_DS_ISO_OVERRIDE_DISABLE|PIN_DS_ISO_BYPASS_DISABLE|ACTIVE_STATE_VAL|PIN_DS_INPUT|PIN_SCMITT_TRIGGER_ENABLE, 0) /* (B12) MCU_RESETSTATz */
			AM62X_MCU_IOPAD(0x0054, WKUP_DISABLE|PIN_DEBOUNCE_DISABLE|PIN_DS_FORCE_DISABLE|PIN_INPUT_PULLUP|PIN_DRIVE_STRENGTH_NOMINAL|PIN_DS_ISO_OVERRIDE_DISABLE|PIN_DS_ISO_BYPASS_DISABLE|ACTIVE_STATE_VAL|PIN_DS_INPUT|PIN_SCMITT_TRIGGER_ENABLE, 0) /* (E11) MCU_RESETz */
		>;
	};
	mcu_uart1_pins_default: mcu_uart1-default-pins {
		pinctrl-single,pins = <
			AM62X_MCU_IOPAD(0x001c, WKUP_DISABLE|PIN_DEBOUNCE_DISABLE|PIN_DS_FORCE_DISABLE|PIN_INPUT|PIN_DRIVE_STRENGTH_NOMINAL|PIN_DS_ISO_OVERRIDE_DISABLE|PIN_DS_ISO_BYPASS_DISABLE|ACTIVE_STATE_VAL|PIN_DS_INPUT|PIN_SCMITT_TRIGGER_ENABLE, 0) /* (A6) MCU_UART0_CTSn */
			AM62X_MCU_IOPAD(0x0020, WKUP_DISABLE|PIN_DEBOUNCE_DISABLE|PIN_DS_FORCE_DISABLE|PIN_OUTPUT|PIN_DRIVE_STRENGTH_NOMINAL|PIN_DS_ISO_OVERRIDE_DISABLE|PIN_DS_ISO_BYPASS_DISABLE|ACTIVE_STATE_VAL|PIN_DS_INPUT|PIN_SCMITT_TRIGGER_ENABLE, 0) /* (B6) MCU_UART0_RTSn */
			AM62X_MCU_IOPAD(0x0014, WKUP_DISABLE|PIN_DEBOUNCE_DISABLE|PIN_DS_FORCE_DISABLE|PIN_INPUT|PIN_DRIVE_STRENGTH_NOMINAL|PIN_DS_ISO_OVERRIDE_DISABLE|PIN_DS_ISO_BYPASS_DISABLE|ACTIVE_STATE_VAL|PIN_DS_INPUT|PIN_SCMITT_TRIGGER_ENABLE, 0) /* (B5) MCU_UART0_RXD */
			AM62X_MCU_IOPAD(0x0018, WKUP_DISABLE|PIN_DEBOUNCE_DISABLE|PIN_DS_FORCE_DISABLE|PIN_OUTPUT|PIN_DRIVE_STRENGTH_NOMINAL|PIN_DS_ISO_OVERRIDE_DISABLE|PIN_DS_ISO_BYPASS_DISABLE|ACTIVE_STATE_VAL|PIN_DS_INPUT|PIN_SCMITT_TRIGGER_ENABLE, 0) /* (A5) MCU_UART0_TXD */
		>;
	};
	wkup_system1_pins_default: wkup_system1-default-pins {
		pinctrl-single,pins = <
			AM62X_MCU_IOPAD(0x0080, WKUP_DISABLE|PIN_DEBOUNCE_DISABLE|PIN_DS_FORCE_DISABLE|PIN_OUTPUT|PIN_DRIVE_STRENGTH_NOMINAL|PIN_DS_ISO_OVERRIDE_DISABLE|PIN_DS_ISO_BYPASS_DISABLE|ACTIVE_STATE_VAL|PIN_DS_INPUT|PIN_SCMITT_TRIGGER_ENABLE, 0) /* (B7) PMIC_LPM_EN0 */
			AM62X_MCU_IOPAD(0x0084, WKUP_DISABLE|PIN_DEBOUNCE_DISABLE|PIN_DS_FORCE_DISABLE|PIN_OUTPUT|PIN_DRIVE_STRENGTH_NOMINAL|PIN_DS_ISO_OVERRIDE_DISABLE|PIN_DS_ISO_BYPASS_DISABLE|ACTIVE_STATE_VAL|PIN_DS_OUTPUT_LOW|PIN_SCMITT_TRIGGER_ENABLE, 0) /* (A12) WKUP_CLKOUT0 Pin not configured */
		>;
	};
	mymcu_gpio09_notconf_pins_default: mymcu_gpio09_notconf-default-pins {
		pinctrl-single,pins = <
			AM62X_MCU_IOPAD(0x0024, WKUP_DISABLE|PIN_DEBOUNCE_DISABLE|PIN_DS_FORCE_DISABLE|PIN_OUTPUT|PIN_DRIVE_STRENGTH_NOMINAL|PIN_DS_ISO_OVERRIDE_DISABLE|PIN_DS_ISO_BYPASS_DISABLE|ACTIVE_STATE_VAL|PIN_DS_OUTPUT_LOW|PIN_SCMITT_TRIGGER_ENABLE, 7) /* (B4) WKUP_UART0_RXD.MCU_GPIO0_9 Pin not configured */
		>;
	};
	mymcu_gpio010_notconf_pins_default: mymcu_gpio010_notconf-default-pins {
		pinctrl-single,pins = <
			AM62X_MCU_IOPAD(0x0028, WKUP_DISABLE|PIN_DEBOUNCE_DISABLE|PIN_DS_FORCE_DISABLE|PIN_OUTPUT|PIN_DRIVE_STRENGTH_NOMINAL|PIN_DS_ISO_OVERRIDE_DISABLE|PIN_DS_ISO_BYPASS_DISABLE|ACTIVE_STATE_VAL|PIN_DS_OUTPUT_LOW|PIN_SCMITT_TRIGGER_ENABLE, 7) /* (C5) WKUP_UART0_TXD.MCU_GPIO0_10 Pin not configured */
		>;
	};
	mymcu_gpio011_notconf_pins_default: mymcu_gpio011_notconf-default-pins {
		pinctrl-single,pins = <
			AM62X_MCU_IOPAD(0x002c, WKUP_DISABLE|PIN_DEBOUNCE_DISABLE|PIN_DS_FORCE_DISABLE|PIN_OUTPUT|PIN_DRIVE_STRENGTH_NOMINAL|PIN_DS_ISO_OVERRIDE_DISABLE|PIN_DS_ISO_BYPASS_DISABLE|ACTIVE_STATE_VAL|PIN_DS_OUTPUT_LOW|PIN_SCMITT_TRIGGER_ENABLE, 7) /* (C6) WKUP_UART0_CTSn.MCU_GPIO0_11 Pin not configured */
		>;
	};
	mymcu_gpio012_notconf_pins_default: mymcu_gpio012_notconf-default-pins {
		pinctrl-single,pins = <
			AM62X_MCU_IOPAD(0x0030, WKUP_DISABLE|PIN_DEBOUNCE_DISABLE|PIN_DS_FORCE_DISABLE|PIN_OUTPUT|PIN_DRIVE_STRENGTH_NOMINAL|PIN_DS_ISO_OVERRIDE_DISABLE|PIN_DS_ISO_BYPASS_DISABLE|ACTIVE_STATE_VAL|PIN_DS_OUTPUT_LOW|PIN_SCMITT_TRIGGER_ENABLE, 7) /* (A4) WKUP_UART0_RTSn.MCU_GPIO0_12 Pin not configured */
		>;
	};
	mymcu_gpio013_notconf_pins_default: mymcu_gpio013_notconf-default-pins {
		pinctrl-single,pins = <
			AM62X_MCU_IOPAD(0x0034, WKUP_DISABLE|PIN_DEBOUNCE_DISABLE|PIN_DS_FORCE_DISABLE|PIN_OUTPUT|PIN_DRIVE_STRENGTH_NOMINAL|PIN_DS_ISO_OVERRIDE_DISABLE|PIN_DS_ISO_BYPASS_DISABLE|ACTIVE_STATE_VAL|PIN_DS_OUTPUT_LOW|PIN_SCMITT_TRIGGER_ENABLE, 7) /* (D6) MCU_MCAN0_TX.MCU_GPIO0_13 Pin not configured */
		>;
	};
	mymcu_gpio014_notconf_pins_default: mymcu_gpio014_notconf-default-pins {
		pinctrl-single,pins = <
			AM62X_MCU_IOPAD(0x0038, WKUP_DISABLE|PIN_DEBOUNCE_DISABLE|PIN_DS_FORCE_DISABLE|PIN_OUTPUT|PIN_DRIVE_STRENGTH_NOMINAL|PIN_DS_ISO_OVERRIDE_DISABLE|PIN_DS_ISO_BYPASS_DISABLE|ACTIVE_STATE_VAL|PIN_DS_OUTPUT_LOW|PIN_SCMITT_TRIGGER_ENABLE, 7) /* (B3) MCU_MCAN0_RX.MCU_GPIO0_14 Pin not configured */
		>;
	};
	mymcu_gpio016_notconf_pins_default: mymcu_gpio016_notconf-default-pins {
		pinctrl-single,pins = <
			AM62X_MCU_IOPAD(0x0040, WKUP_DISABLE|PIN_DEBOUNCE_DISABLE|PIN_DS_FORCE_DISABLE|PIN_OUTPUT|PIN_DRIVE_STRENGTH_NOMINAL|PIN_DS_ISO_OVERRIDE_DISABLE|PIN_DS_ISO_BYPASS_DISABLE|ACTIVE_STATE_VAL|PIN_DS_OUTPUT_LOW|PIN_SCMITT_TRIGGER_ENABLE, 7) /* (D4) MCU_MCAN1_RX.MCU_GPIO0_16 Pin not configured */
		>;
	};
	mymcu_gpio019_notconf_pins_default: mymcu_gpio019_notconf-default-pins {
		pinctrl-single,pins = <
			AM62X_MCU_IOPAD(0x004c, WKUP_DISABLE|PIN_DEBOUNCE_DISABLE|PIN_DS_FORCE_DISABLE|PIN_INPUT|PIN_DRIVE_STRENGTH_NOMINAL|PIN_DS_ISO_OVERRIDE_DISABLE|PIN_DS_ISO_BYPASS_DISABLE|ACTIVE_STATE_VAL|PIN_DS_OUTPUT_LOW|PIN_SCMITT_TRIGGER_ENABLE, 7) /* (B9) WKUP_I2C0_SCL.MCU_GPIO0_19 Pin not configured */
		>;
	};
	mymcu_gpio020_notconf_pins_default: mymcu_gpio020_notconf-default-pins {
		pinctrl-single,pins = <
			AM62X_MCU_IOPAD(0x0050, WKUP_DISABLE|PIN_DEBOUNCE_DISABLE|PIN_DS_FORCE_DISABLE|PIN_INPUT|PIN_DRIVE_STRENGTH_NOMINAL|PIN_DS_ISO_OVERRIDE_DISABLE|PIN_DS_ISO_BYPASS_DISABLE|ACTIVE_STATE_VAL|PIN_DS_OUTPUT_LOW|PIN_SCMITT_TRIGGER_ENABLE, 7) /* (A9) WKUP_I2C0_SDA.MCU_GPIO0_20 Pin not configured */
		>;
	};
};
